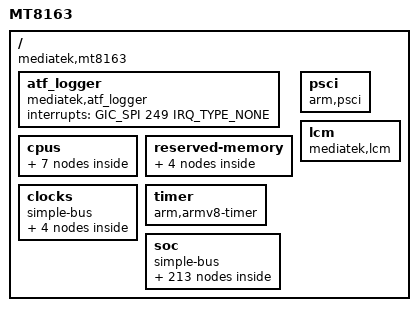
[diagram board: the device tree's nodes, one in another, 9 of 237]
/*
 * Mediatek's MT8163 SoC device tree source
 * Copyright (c) 2014-2015 MediaTek Inc.
 *
 * This program is free software; you can redistribute it and/or modify
 * it under the terms of the GNU General Public License version 2 as
 * published by the Free Software Foundation.
 *
 * This program is distributed in the hope that it will be useful,
 * MERCHANTABILITY or FITNESS FOR A PARTICULAR PURPOSE.  See the
 * GNU General Public License for more details.
 */

#include <dt-bindings/clock/mt8163-clk.h>
#include <dt-bindings/power/mt8163-power.h>
#include <dt-bindings/interrupt-controller/irq.h>
#include <dt-bindings/interrupt-controller/arm-gic.h>
#include <dt-bindings/reset-controller/mt8163-resets.h>
#include <dt-bindings/soc/mt8163-md32.h>
#include "mt8163-pinfunc.h"

/ {
	model = "MT8163";
	compatible = "mediatek,mt8163";
	interrupt-parent = <&sysirq>;
	#address-cells = <2>;
	#size-cells = <2>;

	/* ATF logger SW IRQ number 281 = 32 + 249 */
	atf_logger {
		compatible = "mediatek,atf_logger";
		interrupts = <GIC_SPI 249 IRQ_TYPE_NONE>;
	};

	cpus {
		#address-cells = <1>;
		#size-cells = <0>;

		cpu0: cpu@0 {
			device_type = "cpu";
			compatible = "arm,cortex-a53";
			reg = <0x0>;
			enable-method = "mt-boot";
			cpu-idle-states = <&CLUSTER_SLEEP_0 &CLUSTER_SLEEP_0>,
					  <&CPU_SLEEP_0_0 &CPU_SLEEP_0_0 &CPU_SLEEP_0_0>;
			cpu-release-addr = <0x0 0x40000200>;
			clock-frequency = <1300000000>;
		};

		cpu1: cpu@1 {
			device_type = "cpu";
			compatible = "arm,cortex-a53";
			reg = <0x1>;
			enable-method = "mt-boot";
			cpu-idle-states = <&CLUSTER_SLEEP_0 &CLUSTER_SLEEP_0>,
					  <&CPU_SLEEP_0_0 &CPU_SLEEP_0_0 &CPU_SLEEP_0_0>;
			cpu-release-addr = <0x0 0x40000200>;
			clock-frequency = <1300000000>;
		};

		cpu2: cpu@2 {
			device_type = "cpu";
			compatible = "arm,cortex-a53";
			reg = <0x2>;
			enable-method = "mt-boot";
			cpu-idle-states = <&CLUSTER_SLEEP_0 &CLUSTER_SLEEP_0>,
					  <&CPU_SLEEP_0_0 &CPU_SLEEP_0_0 &CPU_SLEEP_0_0>;
			cpu-release-addr = <0x0 0x40000200>;
			clock-frequency = <1300000000>;
		};

		cpu3: cpu@3 {
			device_type = "cpu";
			compatible = "arm,cortex-a53";
			reg = <0x3>;
			enable-method = "mt-boot";
			cpu-idle-states = <&CLUSTER_SLEEP_0 &CLUSTER_SLEEP_0>,
					  <&CPU_SLEEP_0_0 &CPU_SLEEP_0_0 &CPU_SLEEP_0_0>;
			cpu-release-addr = <0x0 0x40000200>;
			clock-frequency = <1300000000>;
		};

		idle-states {
			entry-method = "arm,psci";

			CPU_SLEEP_0_0: cpu-sleep-0-0 {
				compatible = "arm,idle-state";
				arm,psci-suspend-param = <0x0010000>;
				entry-latency-us = <600>;
				exit-latency-us = <600>;
				min-residency-us = <1200>;
			};

			CLUSTER_SLEEP_0: cluster-sleep-0 {
				compatible = "arm,idle-state";
				arm,psci-suspend-param = <0x2010000>;
				entry-latency-us = <800>;
				exit-latency-us = <1000>;
				min-residency-us = <2000>;
			};
		};
	};

	reserved-memory {
		#address-cells = <2>;
		#size-cells = <2>;
		ranges;

		atf-reserved-memory@43000000 {
			compatible = "mediatek,mt8163-atf-reserved-memory";
			no-map;
			reg = <0 0x43000000 0 0x30000>;
		};

		ram_console-reserved-memory@44400000{
			compatible = "mediatek,ram_console";
			reg = <0 0x44400000 0 0x10000>;
		};

		minirdump-reserved-memory@444f0000{
			compatible = "mediatek,minirdump";
			reg = <0 0x444f0000 0 0x10000>;
		};

		consys-reserve-memory {
			compatible = "mediatek,consys-reserve-memory";
			no-map;
			size = <0 0x200000>;
			alignment = <0 0x200000>;
		};
	};

	psci {
		compatible  = "arm,psci";
		method      = "smc";
		cpu_suspend = <0x84000001>;
		cpu_off     = <0x84000002>;
		cpu_on      = <0x84000003>;
		affinity_info = <0x84000004>;
	};

	clocks {
		#address-cells = <2>;
		#size-cells = <2>;
		compatible = "simple-bus";
		ranges;

		clk_null: clk_null {
			compatible = "fixed-clock";
			#clock-cells = <0>;
			clock-frequency = <0>;
		};

		clk26m: clk26m {
			compatible = "fixed-clock";
			#clock-cells = <0>;
			clock-frequency = <26000000>;
		};

		clk32k: clk32k {
			compatible = "fixed-clock";
			#clock-cells = <0>;
			clock-frequency = <32000>;
		};

		uart_clk: dummy26m {
			compatible = "fixed-clock";
			clock-frequency = <26000000>;
			#clock-cells = <0>;
		};
	};

	timer {
		compatible = "arm,armv8-timer";
		interrupt-parent = <&gic>;
		interrupts = <GIC_PPI 13
			     (GIC_CPU_MASK_SIMPLE(4) | IRQ_TYPE_LEVEL_LOW)>,
			     <GIC_PPI 14
			     (GIC_CPU_MASK_SIMPLE(4) | IRQ_TYPE_LEVEL_LOW)>,
			     <GIC_PPI 11
			     (GIC_CPU_MASK_SIMPLE(4) | IRQ_TYPE_LEVEL_LOW)>,
			     <GIC_PPI 10
			     (GIC_CPU_MASK_SIMPLE(4) | IRQ_TYPE_LEVEL_LOW)>;
		clock-frequency = <13000000>;
	};

	soc {
		#address-cells = <2>;
		#size-cells = <2>;
		compatible = "simple-bus";
		ranges;

		chipid: chipid@08000000 {
			compatible = "mediatek,mt8163-chipid";
			reg = <0 0x08000000 0 0x0010>;
		};

		topckgen: topckgen@10000000 {
			compatible = "mediatek,mt8163-topckgen";
			reg = <0 0x10000000 0 0x1000>;
			#clock-cells = <1>;
		};

		infracfg: infracfg@10001000 {
			compatible = "mediatek,mt8163-infracfg", "syscon";
			reg = <0 0x10001000 0 0x1000>;
			#clock-cells = <1>;
			#reset-cells = <1>;
		};

		syscfg_pctl_a: syscfg_pctl_a@10005000 {
			compatible = "mediatek,mt8163-pctl-a-syscfg", "syscon";
			reg = <0 0x10005000 0 0x1000>;
		};

		toprgu: toprgu@10007000 {
			compatible = "mediatek,mt8163-rgu";
			reg = <0 0x10007000 0 0x1000>;
			interrupts = <GIC_SPI 128 IRQ_TYPE_EDGE_FALLING>;
			#reset-cells = <1>;
		};

		apxgpt: apxgpt@10008000 {
			compatible = "mediatek,mt8163-apxgpt";
			reg = <0 0x10008000 0 0x1000>;
			interrupts = <GIC_SPI 152 IRQ_TYPE_LEVEL_LOW>;
			clocks = <&infracfg CLK_INFRA_APXGPT>,
				 <&infracfg CLK_INFRA_CLK_13M>,
				 <&topckgen CLK_TOP_RTC_SEL>;
			clock-names = "bus",
				      "clk13m",
				      "rtc_sel";
		};

		pmu {
			compatible = "arm,armv8-pmuv3";
			interrupts = <GIC_SPI 8 IRQ_TYPE_LEVEL_LOW>,
				<GIC_SPI 9 IRQ_TYPE_LEVEL_LOW>,
				<GIC_SPI 10 IRQ_TYPE_LEVEL_LOW>,
				<GIC_SPI 11 IRQ_TYPE_LEVEL_LOW>;
			interrupt-affinity = <&cpu0>,
					     <&cpu1>,
					     <&cpu2>,
					     <&cpu3>;
		};

		pio: pinctrl@10005000 {
			compatible = "mediatek,mt8163-pinctrl";
			reg = <0 0x1000B000 0 0x1000>;
			mediatek,pctl-regmap = <&syscfg_pctl_a>;
			pins-are-numbered;
			gpio-controller;
			#gpio-cells = <2>;
			interrupt-controller;
			#interrupt-cells = <2>;
			interrupts = <GIC_SPI 153 IRQ_TYPE_LEVEL_HIGH>,
				     <GIC_SPI 154 IRQ_TYPE_LEVEL_HIGH>,
				     <GIC_SPI 155 IRQ_TYPE_LEVEL_HIGH>;

			spi_pins_a: spi1 {
				pins_spi {
					pinmux = <MT8163_PIN_53_SPI_CS__FUNC_SPI_CSB>,
						 <MT8163_PIN_54_SPI_CK__FUNC_SPI_CLK>,
						 <MT8163_PIN_55_SPI_MI__FUNC_SPI_MI>,
						 <MT8163_PIN_56_SPI_MO__FUNC_SPI_MO>;
					bias-disable;
				};
			};

			/* UART GPIO Settings - Start */
			/* UART0: rx set, rx clear, tx clear, tx clear*/
			uart0_gpio_def_cfg:uart0gpiodefault {

			};
			uart0_rx_set_cfg:uart0_rx_set {
				pins_cmd_dat {
					pinmux = <MT8163_PIN_79_URXD0__FUNC_URXD0>;
				};
			};
			uart0_rx_clr_cfg:uart0_rx_clear  {
				pins_cmd_dat {
					pinmux = <MT8163_PIN_79_URXD0__FUNC_GPIO79>;
					slew-rate = <1>;
					output-high;
				};
			};
			uart0_tx_set_cfg:uart0_tx_set  {
				pins_cmd_dat {
					pinmux = <MT8163_PIN_80_UTXD0__FUNC_UTXD0>;
				};
			};
			uart0_tx_clr_cfg:uart0_tx_clear  {
				pins_cmd_dat {
					pinmux = <MT8163_PIN_80_UTXD0__FUNC_GPIO80>;
					slew-rate = <1>;
					output-high;
				};
			};

			/* UART1: rx set, rx clear, tx clear, tx clear*/
			uart1_gpio_def_cfg:uart1gpiodefault {

			};
			uart1_rx_set_cfg:uart1_rx_set {
				pins_cmd_dat {
					pinmux = <MT8163_PIN_81_URXD1__FUNC_URXD1>;
				};
			};
			uart1_rx_clr_cfg:uart1_rx_clear {
				pins_cmd_dat {
					pinmux = <MT8163_PIN_81_URXD1__FUNC_GPIO81>;
					slew-rate = <1>;
					output-high;
				};
			};
			uart1_tx_set_cfg:uart1_tx_set {
				pins_cmd_dat {
					pinmux = <MT8163_PIN_82_UTXD1__FUNC_UTXD1>;
				};
			};
			uart1_tx_clr_cfg:uart1_tx_clear {
				pins_cmd_dat {
					pinmux = <MT8163_PIN_82_UTXD1__FUNC_GPIO82>;
					slew-rate = <1>;
					output-high;
				};
			};

			/* UART2: rx set, rx clear, tx clear, tx clear*/
			uart2_gpio_def_cfg:uart2gpiodefault {

			};
			uart2_rx_set_cfg:uart2_rx_set {
				pins_cmd_dat {
					pinmux = <MT8163_PIN_14_URXD2__FUNC_URXD2>;
				};
			};
			uart2_rx_clr_cfg:uart2_rx_clear {
				pins_cmd_dat {
					pinmux = <MT8163_PIN_14_URXD2__FUNC_GPIO14>;
					slew-rate = <1>;
					output-high;
				};
			};
			uart2_tx_set_cfg:uart2_tx_set {
				pins_cmd_dat {
					pins = <MT8163_PIN_15_UTXD2__FUNC_UTXD2>;
				};
			};
			uart2_tx_clr_cfg:uart2_tx_clear {
				pins_cmd_dat {
					pinmux = <MT8163_PIN_15_UTXD2__FUNC_GPIO15>;
					slew-rate = <1>;
					output-high;
				};
			};

			/* UART3: rx set, rx clear, tx clear, tx clear*/
			uart3_gpio_def_cfg:uart3gpiodefault {

			};
			uart3_rx_set_cfg:uart3_rx_set {
				pins_cmd_dat {
					pinmux = <MT8163_PIN_16_URXD3__FUNC_URXD3>;
				};
			};
			uart3_rx_clr_cfg:uart3_rx_clear {
				pins_cmd_dat {
					pinmux = <MT8163_PIN_16_URXD3__FUNC_GPIO16>;
					slew-rate = <1>;
					output-high;
				};
			};
			uart3_tx_set_cfg:uart3_tx_set {
				pins_cmd_dat {
					pinmux = <MT8163_PIN_17_UTXD3__FUNC_UTXD3>;
				};
			};
			uart3_tx_clr_cfg:uart3_tx_clear {
				pins_cmd_dat {
					pinmux = <MT8163_PIN_17_UTXD3__FUNC_GPIO17>;
					slew-rate = <1>;
					output-high;
				};
			};

			/* UART GPIO Settings - End */
		};

		dramco: dramco@10004000 {
			compatible = "mediatek,mt8163-dramco";
			reg = <0 0x10004000 0 0x1000>;
		};

		scpsys: scpsys@10006000 {
			compatible = "mediatek,mt8163-scpsys", "syscon";
			#power-domain-cells = <1>;
			reg = <0 0x10006000 0 0x1000>;
			interrupts =	<GIC_SPI 163 IRQ_TYPE_LEVEL_LOW>,
					<GIC_SPI 164 IRQ_TYPE_LEVEL_LOW>,
					<GIC_SPI 165 IRQ_TYPE_LEVEL_LOW>,
					<GIC_SPI 166 IRQ_TYPE_LEVEL_LOW>,
					<GIC_SPI 167 IRQ_TYPE_LEVEL_LOW>,
					<GIC_SPI 168 IRQ_TYPE_LEVEL_LOW>,
					<GIC_SPI 169 IRQ_TYPE_LEVEL_LOW>,
					<GIC_SPI 170 IRQ_TYPE_LEVEL_LOW>;
			infracfg = <&infracfg>;
			clocks = <&topckgen CLK_TOP_MFG_SEL>,
				 <&topckgen CLK_TOP_MM_SEL>;
			clock-names = "mfg", "mm";
		};

		hacc@1000a000 {
			compatible = "mediatek,hacc";
			reg = <0 0x1000a000 0 0x1000>;
			clocks = <&infracfg CLK_INFRA_SEJ>;
			clock-names = "main";
		};

		apmixedsys: apmixedsys@1000c000 {
			compatible = "mediatek,mt8163-apmixedsys";
			reg = <0 0x1000c000 0 0x1000>;
			#clock-cells = <1>;
		};

		fhctl@1000cf00 {
			compatible = "mediatek,mt8163-fhctl";
			reg = <0 0x1000cf00 0 0x100>;
		};

		pwrap: pwrap@0x1000d000 {
			compatible = "mediatek,mt8163-pwrap";
			reg = <0 0x1000d000 0 0x1000>;
			reg-names = "pwrap-base";
			interrupts = <GIC_SPI 161 IRQ_TYPE_LEVEL_HIGH>;
			clocks = <&topckgen CLK_TOP_PMICSPI_SEL>,
				 <&infracfg CLK_INFRA_PMIC_AP>;
			clock-names = "spi",
				      "pwrap";
		};

		devapc_ao@1000e000 {
			compatible = "mediatek,mt8163-devapc_ao";
			reg = <0 0x1000e000 0 0x1000>;
		};

		ddrphy: ddrphy@1000f000 {
			compatible = "mediatek,mt8163-ddrphy", "mediatek,ddrphy";
			reg = <0 0x1000f000 0 0x1000>;
			clocks = <&infracfg CLK_INFRA_DRAMC_F26M>;
			clock-names = "dramc_f26m";
		};

		keypad: keypad@10010000 {
			compatible = "mediatek,mt8163-keypad";
			reg = <0 0x10010000 0 0x1000>;
			interrupts = <GIC_SPI 162 IRQ_TYPE_EDGE_FALLING>;
		};

		md32: md32@10020000 {
			compatible = "mediatek,mt8163-md32";
			reg = <0 0x10020000 0 0x38000>,
			      <0 0x10058000 0 0x400>,
			      <0 0x10059000 0 0x400>;
			interrupts = <GIC_SPI 174 IRQ_TYPE_LEVEL_HIGH>;
			clocks = <&infracfg CLK_INFRA_SCPSYS>;
			clock-names = "sys";
			status = "disabled";
		};

		mcucfg: mcucfg@10200000 {
			compatible = "mediatek,mt8173-mcucfg", "syscon";
			reg = <0 0x10200000 0 0x1000>;
		};

		cpuxgpt: cpuxgpt@10200000 {
			compatible = "mediatek,mt8163-cpuxgpt";
			interrupts = <GIC_SPI 64 IRQ_TYPE_LEVEL_HIGH>,
				<GIC_SPI 65 IRQ_TYPE_LEVEL_HIGH>,
				<GIC_SPI 66 IRQ_TYPE_LEVEL_HIGH>,
				<GIC_SPI 67 IRQ_TYPE_LEVEL_HIGH>;
		};

		lastpc: lastpc@10200000 {
			compatible = "mediatek,mt8163-mcucfg";
			reg = <0 0x10200000 0 0x200>;
		};

		sysirq: intpol-controller@10200620 {
			compatible = "mediatek,mt8163-sysirq",
				     "mediatek,mt6577-sysirq";
			interrupt-controller;
			#interrupt-cells = <3>;
			interrupt-parent = <&gic>;
			reg = <0 0x10200620 0 0x20>;
		};

		emi: emi@10203000 {
			compatible = "mediatek,mt8163-emi", "mediatek,emi";
			reg = <0 0x10203000 0 0x1000>;
			interrupts = <GIC_SPI 133 IRQ_TYPE_LEVEL_HIGH>;
		};

		sys_cirq: sys_cirq@10204000 {
			compatible = "mediatek,mt8163-sys_cirq",
				     "mediatek,mt6735-sys_cirq";
			reg = <0 0x10204000 0 0x1000>;
			interrupts = <GIC_SPI 240 IRQ_TYPE_LEVEL_LOW>;
			mediatek,cirq_num = <169>;
			mediatek,spi_start_offset = <72>;
		};

		m4u@10205000 {
			cell-index = <0>;
			compatible = "mediatek,mt8163-m4u";
			reg = <0 0x10205000 0 0x1000>;
			interrupts = <GIC_SPI 147 IRQ_TYPE_LEVEL_LOW>;
		};

		devapc@10207000 {
			compatible = "mediatek,mt8163-devapc";
			reg = <0 0x10207000 0 0x1000>;
			interrupts = <GIC_SPI 133 IRQ_TYPE_LEVEL_LOW>;
			clocks = <&infracfg CLK_INFRA_DEVICE_APC>;
			clock-names = "main";
		};

		systracker: systracker@10208000 {
			compatible = "mediatek,bus_dbg-v1";
			reg = <0 0x10208000 0 0x1000>;
			interrupts = <GIC_SPI 132 IRQ_TYPE_LEVEL_LOW>;
		};

		dramc_nao: dramc_nao@1020e000 {
			compatible = "mediatek,mt8163-dramc_nao", "mediatek,dramc_nao";
			reg = <0 0x1020e000 0 0x1000>;
		};

		gcpu: gcpu@10210000 {
			compatible = "mediatek,mt8163-gcpu";
			reg = <0 0x10210000 0 0x1000>;
			clocks = <&infracfg CLK_INFRA_GCPU>;
			clock-names = "main";
		};

		gce: gce@10212000 {
			compatible = "mediatek,mt8163-gce";
			reg = <0 0x10212000 0 0x1000>;
			interrupts = <GIC_SPI 143 IRQ_TYPE_LEVEL_LOW>,
				     <GIC_SPI 144 IRQ_TYPE_LEVEL_LOW>;
			disp_mutex_reg = <0x14015000 0x1000>;
			g3d_config_base = <0x13000000 0 0xffff0000>;
			mmsys_config_base = <0x14000000 1 0xffff0000>;
			disp_dither_base = <0x14010000 2 0xffff0000>;
			mm_na_base = <0x14020000 3 0xffff0000>;
			imgsys_base = <0x15000000 4 0xffff0000>;
			vdec_gcon_base = <0x16000000 5 0xffff0000>;
			venc_gcon_base = <0x17000000 6 0xffff0000>;
			conn_peri_base = <0x18000000 7 0xffff0000>;
			topckgen_base = <0x10000000 8 0xffff0000>;
			kp_base = <0x10010000 9 0xffff0000>;
			scp_sram_base = <0x10020000 10 0xffff0000>;
			infra_na3_base = <0x10030000 11 0xffff0000>;
			infra_na4_base = <0x10040000 12 0xffff0000>;
			scp_base = <0x10050000 13 0xffff0000>;
			mcucfg_base = <0x10200000 14 0xffff0000>;
			gcpu_base = <0x10210000 15 0xffff0000>;
			usb0_base = <0x11200000 16 0xffff0000>;
			usb_sif_base = <0x11210000 17 0xffff0000>;
			audio_base = <0x11220000 18 0xffff0000>;
			msdc0_base = <0x11230000 19 0xffff0000>;
			msdc1_base = <0x11240000 20 0xffff0000>;
			msdc2_base = <0x11250000 21 0xffff0000>;
			msdc3_base = <0x11260000 22 0xffff0000>;

			mdp_rdma0_sof = <0>;
			mdp_rsz0_sof = <1>;
			mdp_rsz1_sof = <2>;
			mdp_tdshp_sof = <3>;
			mdp_wdma_sof = <4>;
			mdp_wrot_sof = <5>;
			disp_ovl0_sof = <6>;
			disp_ovl1_sof = <7>;
			disp_rdma0_sof = <8>;
			disp_rdma1_sof = <9>;
			disp_wdma0_sof = <10>;
			disp_color_sof = <11>;
			disp_ccorr_sof = <12>;
			disp_aal_sof = <13>;
			disp_gamma_sof = <14>;
			disp_dither_sof = <15>;
			disp_ufoe_sof = <16>;
			disp_pwm0_sof = <17>;
			disp_wdma1_sof = <18>;
			ufod_rdma0_l0_sof = <19>;
			ufod_rdma0_l1_sof = <20>;
			ufod_rdma0_l2_sof = <21>;
			ufod_rdma0_l3_sof = <22>;
			ufod_rdma1_l0_sof = <23>;
			ufod_rdma1_l1_sof = <24>;
			ufod_rdma1_l2_sof = <25>;
			ufod_rdma1_l3_sof = <26>;
			disp_dsc_sof = <27>;
			mdp_rdma0_frame_done = <28>;
			mdp_rsz0_frame_done = <29>;
			mdp_rsz1_frame_done = <30>;
			mdp_tdshp_frame_done = <31>;
			mdp_wdma_frame_done = <32>;
			mdp_wrot_write_frame_done = <33>;
			mdp_wrot_read_frame_done = <34>;
			disp_ovl0_frame_done = <35>;
			disp_ovl1_frame_done = <36>;
			disp_rdma0_frame_done = <37>;
			disp_rdma1_frame_done = <38>;
			disp_wdma0_frame_done = <39>;
			disp_color_frame_done = <40>;
			disp_ccorr_frame_done = <41>;
			disp_aal_frame_done = <42>;
			disp_gamma_frame_done = <43>;
			disp_dither_frame_done = <44>;
			disp_ufoe_frame_done = <45>;
			disp_dpi0_frame_done = <46>;
			disp_wdma1_frame_done = <47>;
			ufod_rdma0_l0_frame_done = <48>;
			ufod_rdma0_l1_frame_done = <49>;
			ufod_rdma0_l2_frame_done = <50>;
			ufod_rdma0_l3_frame_done = <51>;
			ufod_rdma1_l0_frame_done = <52>;
			ufod_rdma1_l1_frame_done = <53>;
			ufod_rdma1_l2_frame_done = <54>;
			ufod_rdma1_l3_frame_done = <55>;
			disp_dpi1_frame_done = <56>;
			disp_dsc_frame_done = <57>;
			stream_done_0 = <58>;
			stream_done_1 = <59>;
			stream_done_2 = <60>;
			stream_done_3 = <61>;
			stream_done_4 = <62>;
			stream_done_5 = <63>;
			stream_done_6 = <64>;
			stream_done_7 = <65>;
			stream_done_8 = <66>;
			stream_done_9 = <67>;
			buf_underrun_event_0 = <68>;
			buf_underrun_event_1 = <69>;
			dsi0_te_event = <70>;
			isp_frame_done_b = <130>;
			isp_frame_done_a = <131>;
			isp_frame_done_p2_0 = <131>;
			isp_frame_done_p2_1 = <130>;
			seninf_1_fifo_full = <135>;
			venc_done = <257>;
			jpgenc_done = <258>;
			jpgdec_done = <259>;
			venc_mb_done = <260>;
			venc_128byte_cnt_done = <261>;

			clocks = <&infracfg CLK_INFRA_GCE>,
				 <&mmsys CLK_MM_SMI_COMMON>,
				 <&mmsys CLK_MM_SMI_LARB0>,
				 <&mmsys CLK_MM_CAM_MDP>,
				 <&mmsys CLK_MM_MDP_RDMA>,
				 <&mmsys CLK_MM_MDP_RSZ0>,
				 <&mmsys CLK_MM_MDP_RSZ1>,
				 <&mmsys CLK_MM_MDP_TDSHP>,
				 <&mmsys CLK_MM_MDP_WROT>,
				 <&mmsys CLK_MM_MDP_WDMA>;

			clock-names = "MT_CG_INFRA_GCE",
				      "MT_CG_DISP0_SMI_COMMON",
				      "MT_CG_DISP0_SMI_LARB0",
				      "MT_CG_DISP0_CAM_MDP",
				      "MT_CG_DISP0_MDP_RDMA",
				      "MT_CG_DISP0_MDP_RSZ0",
				      "MT_CG_DISP0_MDP_RSZ1",
				      "MT_CG_DISP0_MDP_TDSHP",
				      "MT_CG_DISP0_MDP_WROT",
				      "MT_CG_DISP0_MDP_WDMA";
		};

		perisys_iommu@10214000 {
			cell-index = <1>;
			compatible = "mediatek,mt8163-perisys_iommu";
			reg = <0 0x10214000 0 0x1000>;
			interrupts = <GIC_SPI 145 IRQ_TYPE_LEVEL_LOW>;
		};

		gic: interrupt-controller@10221000 {
			compatible = "arm,gic-400";
			interrupt-controller;
			#interrupt-cells = <3>;
			interrupt-parent = <&gic>;
			reg = <0 0x10221000 0 0x1000>,
			      <0 0x10222000 0 0x1000>,
			      <0 0x10224000 0 0x2000>,
			      <0 0x10226000 0 0x2000>;
			interrupts = <GIC_PPI 9
				     (GIC_CPU_MASK_SIMPLE(4) | IRQ_TYPE_LEVEL_HIGH)>;
		};

		btif_tx: btif_tx@11000700 {
			compatible = "mediatek,btif_tx";
			reg = <0 0x11000700 0 0x80>;
			interrupts = <GIC_SPI 110 IRQ_TYPE_LEVEL_LOW>;
		};

		btif_rx: btif_rx@11000780 {
			compatible = "mediatek,btif_rx";
			reg = <0 0x11000780 0 0x80>;
			interrupts = <GIC_SPI 111 IRQ_TYPE_LEVEL_LOW>;
		};

		auxadc: auxadc@11001000 {
			compatible = "mediatek,mt8163-auxadc",
				     "mediatek,mt6735-auxadc";
			reg = <0 0x11001000 0 0x1000>;
			interrupts = <GIC_SPI 76 IRQ_TYPE_EDGE_FALLING>;
			clocks = <&infracfg CLK_INFRA_AUXADC>;
			clock-names = "auxadc-main";
		};

		uart0: uart0@11002000 {
			cell-index = <0>;
			compatible = "mediatek,mt8163-uart";
			reg = <0 0x11002000 0 0x1000>, /* UART base */
			      <0 0x11000300 0 0x1000>, /* DMA Tx base */
			      <0 0x11000380 0 0x80>; /* DMA Rx base */
			interrupts = <GIC_SPI 91 IRQ_TYPE_LEVEL_LOW>, /* UART IRQ */
				     <GIC_SPI 102 IRQ_TYPE_LEVEL_LOW>, /* DMA Tx IRQ */
				     <GIC_SPI 103 IRQ_TYPE_LEVEL_LOW>; /* DMA Rx IRQ */

			clock-frequency = <26000000>;
			clock-div = <1>;
			clocks = <&infracfg CLK_INFRA_UART0>, <&infracfg CLK_INFRA_AP_DMA>;
			clock-names = "uart0-main", "uart-apdma";
			pinctrl-names = "uart0_gpio_default",
					"uart0_rx_set",
					"uart0_rx_clear",
					"uart0_tx_set",
					"uart0_tx_clear";

			pinctrl-0 = <&uart0_gpio_def_cfg>;
			pinctrl-1 = <&uart0_rx_set_cfg>;
			pinctrl-2 = <&uart0_rx_clr_cfg>;
			pinctrl-3 = <&uart0_tx_set_cfg>;
			pinctrl-4 = <&uart0_tx_clr_cfg>;
			rx_gpios = <&pio 79 0>;
			tx_gpios = <&pio 80 0>;
			status = "okay";
		};

		uart1: uart1@11003000 {
			cell-index = <1>;
			compatible = "mediatek,mt8163-uart";
			reg = <0 0x11003000 0 0x1000>, /* UART base */
			      <0 0x11000400 0 0x80>, /* DMA Tx base */
			      <0 0x11000480 0 0x80>; /* DMA Rx base */
			interrupts = <GIC_SPI 92 IRQ_TYPE_LEVEL_LOW>, /* UART IRQ */
				     <GIC_SPI 104 IRQ_TYPE_LEVEL_LOW>, /* DMA Tx IRQ */
				     <GIC_SPI 105 IRQ_TYPE_LEVEL_LOW>; /* DMA Rx IRQ */

			clock-frequency = <26000000>;
			clock-div = <1>;
			clocks = <&infracfg CLK_INFRA_UART1>;
			clock-names = "uart1-main";

			pinctrl-names = "uart1_gpio_default",
					"uart1_rx_set",
					"uart1_rx_clear",
					"uart1_tx_set",
					"uart1_tx_clear";

			pinctrl-0 = <&uart1_gpio_def_cfg>;
			pinctrl-1 = <&uart1_rx_set_cfg>;
			pinctrl-2 = <&uart1_rx_clr_cfg>;
			pinctrl-3 = <&uart1_tx_set_cfg>;
			pinctrl-4 = <&uart1_tx_clr_cfg>;
			rx_gpios = <&pio 81 0>;
			tx_gpios = <&pio 82 0>;
			status = "disable";
		};

		uart2: uart2@11004000 {
			cell-index = <2>;
			compatible = "mediatek,mt8163-uart";
			reg = <0 0x11004000 0 0x1000>, /* UART base */
			      <0 0x11000500 0 0x80>, /* DMA Tx base */
			      <0 0x11000580 0 0x80>; /* DMA Rx base */
			interrupts = <GIC_SPI 93 IRQ_TYPE_LEVEL_LOW>, /* UART IRQ */
				     <GIC_SPI 106 IRQ_TYPE_LEVEL_LOW>, /* DMA Tx IRQ */
				     <GIC_SPI 107 IRQ_TYPE_LEVEL_LOW>; /* DMA Rx IRQ */

			clock-frequency = <26000000>;
			clock-div = <1>;
			clocks = <&infracfg CLK_INFRA_UART2>;
			clock-names = "uart2-main";
			pinctrl-names = "uart2_gpio_default",
					"uart2_rx_set",
					"uart2_rx_clear",
					"uart2_tx_set",
					"uart2_tx_clear";

			pinctrl-0 = <&uart2_gpio_def_cfg>;
			pinctrl-1 = <&uart2_rx_set_cfg>;
			pinctrl-2 = <&uart2_rx_clr_cfg>;
			pinctrl-3 = <&uart2_tx_set_cfg>;
			pinctrl-4 = <&uart2_tx_clr_cfg>;
			rx_gpios = <&pio 14 0>;
			tx_gpios = <&pio 15 0>;
			status = "disable";
		};

		uart3: uart3@11005000 {
			cell-index = <3>;
			compatible = "mediatek,mt8163-uart";
			reg = <0 0x11005000 0 0x1000>, /* UART base */
			      <0 0x11000600 0 0x80>, /* DMA Tx base */
			      <0 0x11000680 0 0x80>; /* DMA Rx base */
			interrupts = <GIC_SPI 94 IRQ_TYPE_LEVEL_LOW>, /* UART IRQ */
				     <GIC_SPI 108 IRQ_TYPE_LEVEL_LOW>, /* DMA Tx IRQ */
				     <GIC_SPI 109 IRQ_TYPE_LEVEL_LOW>; /* DMA Rx IRQ */

			clock-frequency = <26000000>;
			clock-div = <1>;
			clocks = <&infracfg CLK_INFRA_UART3>;
			clock-names = "uart3-main";

			pinctrl-names = "uart3_gpio_default",
					"uart3_rx_set",
					"uart3_rx_clear",
					"uart3_tx_set",
					"uart3_tx_clear";

			pinctrl-0 = <&uart3_gpio_def_cfg>;
			pinctrl-1 = <&uart3_rx_set_cfg>;
			pinctrl-2 = <&uart3_rx_clr_cfg>;
			pinctrl-3 = <&uart3_tx_set_cfg>;
			pinctrl-4 = <&uart3_tx_clr_cfg>;
			rx_gpios = <&pio 16 0>;
			tx_gpios = <&pio 17 0>;
			status = "disable";
		};

		pwm: pwm@11006000 {
			compatible = "mediatek,mt8163-pwm";
			reg = <0 0x11006000 0 0x1000>;
			interrupts = <GIC_SPI 77 IRQ_TYPE_LEVEL_LOW>;
			clocks = <&infracfg CLK_INFRA_PWM>,
				 <&infracfg CLK_INFRA_PWM1>,
				 <&infracfg CLK_INFRA_PWM2>,
				 <&infracfg CLK_INFRA_PWM3>;

			clock-names = "PWM-main",
				      "PWM1-main",
				      "PWM2-main",
				      "PWM3-main";
		};

		i2c0: i2c@11007000 {
			compatible = "mediatek,mt8173-i2c";
			reg = <0 0x11007000 0 0x70>,
			      <0 0x11000180 0 0x80>;
			interrupts = <GIC_SPI 84 IRQ_TYPE_LEVEL_LOW>;
			clock-div = <10>;
			clocks = <&infracfg CLK_INFRA_I2C0>, <&infracfg CLK_INFRA_AP_DMA>;
			clock-names = "main", "dma";
			#address-cells = <1>;
			#size-cells = <0>;
			status = "disabled";
		};

		i2c1: i2c@11008000 {
			compatible = "mediatek,mt8173-i2c";
			reg = <0 0x11008000 0 0x70>,
			      <0 0x11000200 0 0x80>;
			interrupts = <GIC_SPI 85 IRQ_TYPE_LEVEL_LOW>;
			clock-div = <10>;
			clocks = <&infracfg CLK_INFRA_I2C1>, <&infracfg CLK_INFRA_AP_DMA>;
			clock-names = "main", "dma";
			#address-cells = <1>;
			#size-cells = <0>;
			status = "disabled";
		};

		i2c2: i2c@11009000 {
			compatible = "mediatek,mt8173-i2c";
			reg = <0 0x11009000 0 0x70>,
			      <0 0x11000280 0 0x80>;
			interrupts = <GIC_SPI 86 IRQ_TYPE_LEVEL_LOW>;
			clock-div = <10>;
			clocks = <&infracfg CLK_INFRA_I2C2>, <&infracfg CLK_INFRA_AP_DMA>;
			clock-names = "main", "dma";
			#address-cells = <1>;
			#size-cells = <0>;
			status = "disabled";
		};

		spi: spi@1100a000 {
			compatible = "mediatek,mt8163-spi";
			#address-cells = <1>;
			#size-cells = <0>;
			reg = <0 0x1100a000 0 0x1000>;
			interrupts = <GIC_SPI 118 IRQ_TYPE_LEVEL_LOW>;
			clocks = <&topckgen CLK_TOP_SYSPLL3_D2>,
				 <&topckgen CLK_TOP_SPI_SEL>,
				 <&infracfg CLK_INFRA_SPI>;
			clock-names = "parent-clk", "sel-clk", "spi-clk";
			pinctrl-names = "default";
			pinctrl-0 = <&spi_pins_a>;
			status = "disabled";
		};

		thermal: thermal@1100b000 {
			compatible = "mediatek,mt8163-thermal";
			reg = <0 0x1100b000 0 0x1000>;
			interrupts = <GIC_SPI 78 IRQ_TYPE_LEVEL_LOW>;
			clocks = <&infracfg CLK_INFRA_THERM>, <&infracfg CLK_INFRA_AUXADC>;
			clock-names = "therm", "auxadc";
			apmixedsys = <&apmixedsys>;
		};

		ptp_od: ptp_od@1100b000 {
			compatible = "mediatek,mt8163-ptp_od";
			reg = <0 0x1100b000 0 0x1000>;
			interrupts = <GIC_SPI 125 IRQ_TYPE_LEVEL_LOW>;
			clocks = <&infracfg CLK_INFRA_THERM>;
			clock-names = "ptp_infra_therm";
		};

		btif: btif@1100c000 {
			compatible = "mediatek,btif";
			reg = <0 0x1100c000 0 0x1000>;
			interrupts = <GIC_SPI 112 IRQ_TYPE_LEVEL_LOW>;
			clocks = <&infracfg CLK_INFRA_BTIF>, <&infracfg CLK_INFRA_AP_DMA>;
			clock-names = "btifc", "apdmac";
		};/* End of btif */

		nfi: nfi@1100d000 {
			compatible = "mediatek,mt8163-nfi";
			reg = <0 0x1100d000 0 0x1000>;
			interrupts = <GIC_SPI 96 IRQ_TYPE_LEVEL_LOW>;
			clocks = <&infracfg CLK_INFRA_NFI>, <&infracfg CLK_INFRA_NFI_ECC>,
				 <&infracfg CLK_INFRA_NFI_BCLK>, <&topckgen CLK_TOP_ONFI_SEL>,
				 <&clk26m>, <&topckgen CLK_TOP_SYSPLL2_D2>,
				 <&topckgen CLK_TOP_SYSPLL_D7>, <&infracfg CLK_INFRA_NFI_SEL>,
				 <&topckgen CLK_TOP_AXI_SEL>, <&infracfg CLK_INFRA_ONFI_D2>,
				 <&infracfg CLK_INFRA_NFI_ECC_66M>, <&infracfg CLK_INFRA_NFI_66M>,
				 <&infracfg CLK_INFRA_ONFI>;
			clock-names = "nfi_hclk", "nfiecc_bclk", "nfi_bclk",
				      "onfi_sel", "onfi_clk26m", "onfi_mode5",
				      "onfi_mode4", "nfi_bclk_sel", "nfi_ahb_clk",
				      "nfi_1xpad_clk", "nfiecc_pclk", "nfi_pclk",
				      "onfi_pad_clk";
		};

		nfiecc: nfiecc@1100e000 {
			compatible = "mediatek,mt8163-nfiecc";
			reg = <0 0x1100e000 0 0x1000>;
			interrupts = <GIC_SPI 95 IRQ_TYPE_LEVEL_LOW>;
		};

		usb0: usb@11200000 {
			compatible = "mediatek,mt8163-usb20";
			reg = <0 0x11200000 0 0x10000>,
			      <0 0x11210000 0 0x10000>;
			interrupts = <GIC_SPI 72 IRQ_TYPE_LEVEL_LOW>;
			mode = <2>;
			multipoint = <1>;
			dyn_fifo = <1>;
			soft_con = <1>;
			dma = <1>;
			num_eps = <16>;
			dma_channels = <8>;
			clocks = <&apmixedsys CLK_APMIXED_UNIVPLL>,
				 <&infracfg CLK_INFRA_USB_MCU>,
				 <&infracfg CLK_INFRA_USB>;
			clock-names = "usbpll", "usbmcu", "usb";
		};

		audiosys: audiosys@11220000 {
			compatible = "mediatek,mt8163-audiosys", "syscon";
			reg = <0 0x11220000 0 0x1000>;
			#clock-cells = <1>;
		};

		audgpio: mt_soc_dl1_pcm@11220000 {
			compatible = "mediatek,mt8163-soc-pcm-dl1";
			reg = <0 0x11220000 0 0x1000>,
			      <0 0x11221000 0 0x9000>;
			interrupts = <GIC_SPI 142 IRQ_TYPE_LEVEL_LOW>;
			clocks = <&infracfg CLK_INFRA_AUDIO>,
				 <&topckgen CLK_TOP_AUDIO_SEL>,
				 <&topckgen CLK_TOP_AUD_INTBUS_SEL>,
				 <&topckgen CLK_TOP_AUD_1_SEL>,
				 <&topckgen CLK_TOP_AUD_2_SEL>,
				 <&topckgen CLK_TOP_APLL1>,
				 <&topckgen CLK_TOP_APLL2>,
				 <&clk26m>;
			clock-names = "aud_infra_clk",
				      "top_mux_audio",
				      "top_mux_audio_intbus",
				      "aud_mux1_clk",
				      "aud_mux2_clk",
				      "top_apll1_clk",
				      "top_apll2_clk",
				      "top_clk26m_clk";
			power-domains = <&scpsys MT8163_POWER_DOMAIN_AUDIO>;
		};

		mt_soc_dl2_pcm@11220000 {
			compatible = "mediatek,mt8163-soc-pcm-dl2";
		};

		mt_soc_ul1_pcm@11220000 {
			compatible = "mediatek,mt8163-soc-pcm-capture";
		};

		mt_soc_voice_md1@11220000 {
			compatible = "mediatek,mt8163-soc-pcm-voice-md1";
		};

		mt_soc_hdmi_pcm@11220000 {
			compatible = "mediatek,mt8163-soc-pcm-hdmi";
		};

		mt_soc_uldlloopback@11220000 {
			compatible = "mediatek,mt8163-soc-pcm-uldlloopback";
		};

		mt_soc_i2s0_pcm@11220000 {
			compatible = "mediatek,mt8163-soc-pcm-dl1-i2s0";
		};

		mt_soc_mrgrx_pcm@11220000 {
			compatible = "mediatek,mt8163-soc-pcm-mrgrx";
		};

		mt_soc_mrgrx_awb_pcm@11220000 {
			compatible = "mediatek,mt8163-soc-pcm-mrgrx-awb";
		};

		mt_soc_fm_i2s_pcm@11220000 {
			compatible = "mediatek,mt8163-soc-pcm-fm-i2s";
		};

		mt_soc_fm_i2s_awb_pcm@11220000 {
			compatible = "mediatek,mt8163-soc-pcm-fm-i2s-awb";
		};

		mt_soc_i2s0dl1_pcm@11220000 {
			compatible = "mediatek,mt8163-soc-pcm-dl1-i2s0Dl1";
		};

		mt_soc_dl1_awb_pcm@11220000 {
			compatible = "mediatek,mt8163-soc-pcm-dl1-awb";
		};

		mt_soc_voice_md1_bt@11220000 {
			compatible = "mediatek,mt8163-soc-pcm-voice-md1-bt";
		};

		mt_soc_voip_bt_out@11220000 {
			compatible = "mediatek,mt8163-soc-pcm-dl1-bt";
		};

		mt_soc_voip_bt_in@11220000 {
			compatible = "mediatek,mt8163-soc-pcm-bt-dai";
		};

		mt_soc_tdmrx_pcm@11220000 {
			compatible = "mediatek,mt8163-soc-tdm-capture";
		};

		mt_soc_fm_mrgtx_pcm@11220000 {
			compatible = "mediatek,mt8163-soc-pcm-fmtx";
		};

		mt_soc_ul2_pcm@11220000 {
			compatible = "mediatek,mt8163-soc-pcm-capture2";
		};

		mt_soc_i2s0_awb_pcm@11220000 {
			compatible = "mediatek,mt8163-soc-pcm-i2s0-awb";
		};

		mt_soc_voice_md2@11220000 {
			compatible = "mediatek,mt8163-soc-pcm-voice-md2";
		};

		mt_soc_routing_pcm@11220000 {
			compatible = "mediatek,mt8163-soc-pcm-routing";
		};

		mt_soc_voice_md2_bt@11220000 {
			compatible = "mediatek,mt8163-soc-pcm-voice-md2-bt";
		};

		mt_soc_hp_impedance@11220000 {
			compatible = "mediatek,mt8163-soc-pcm-hp-impedance";
		};

		mt_soc_codec_name@11220000 {
			compatible = "mediatek,mt8163-soc-codec-63xx";
		};

		mt_soc_dummy_pcm@11220000 {
			compatible = "mediatek,mt8163-soc-pcm-dummy";
		};

		mt_soc_codec_dummy_name@11220000 {
			compatible = "mediatek,mt8163-soc-codec-dummy";
		};

		mt_soc_routing_dai_name@11220000 {
			compatible = "mediatek,mt8163-soc-dai-routing";
		};

		mt_soc_dai_name@11220000 {
			compatible = "mediatek,mt8163-soc-dai-stub";
		};

		mfg: mfg@13000000 {
			compatible = "mediatek,mt8163-mfg", "mediatek,midgard-mfg";
			reg = <0 0x13000000 0 0x1000>;
			clocks = <&topckgen CLK_TOP_MFG_SEL>,
				 <&topckgen CLK_TOP_MMPLL>;
			clock-names = "topck", "pll";
		};

		mali: gpu@13040000 {
			compatible = "arm,malit720", "arm,mali-t72x", "arm,malit7xx", "arm,mali-midgard";
			reg = <0 0x13040000 0 0x4000>;
			interrupts = <GIC_SPI 227 IRQ_TYPE_LEVEL_LOW>,
				     <GIC_SPI 226 IRQ_TYPE_LEVEL_LOW>,
				     <GIC_SPI 225 IRQ_TYPE_LEVEL_LOW>;
			interrupt-names = "JOB", "MMU", "GPU";
			clock-frequency = <520000000>;
			power-domains = <&scpsys MT8163_POWER_DOMAIN_MFG>;
		};

		mmc0: mmc@11230000 {
			compatible = "mediatek,mt8163-mmc";
			reg = <0 0x11230000 0 0x1000>;
			interrupts = <GIC_SPI 79 IRQ_TYPE_LEVEL_LOW>;
			clocks = <&infracfg CLK_INFRA_MSDC0>,
				 <&infracfg CLK_INFRA_MSDC3>;
			clock-names = "source", "hclk";
			status = "disabled";
		};

		mmc1: mmc@11240000 {
			compatible = "mediatek,mt8163-mmc";
			reg = <0 0x11240000 0 0x1000>;
			interrupts = <GIC_SPI 80 IRQ_TYPE_LEVEL_LOW>;
			clocks = <&infracfg CLK_INFRA_MSDC1>,
				 <&clk_null>;
			clock-names = "source", "hclk";
			status = "disabled";
		};

		usb1: usb@11270000 {
			compatible = "mediatek,mt8163-usb11";
			cell-index = <1>;
			reg = <0 0x11270000 0 0x10000>,
			      <0 0x11210000 0 0x10000>;
			interrupts = <GIC_SPI 73 IRQ_TYPE_LEVEL_LOW>;
			mode = <2>;
			multipoint = <1>;
			dyn_fifo = <1>;
			soft_con = <1>;
			dma = <1>;
			num_eps = <8>;
			dma_channels = <4>;
			clocks = <&apmixedsys CLK_APMIXED_UNIVPLL>,
				 <&infracfg CLK_INFRA_USB_MCU>,
				 <&infracfg CLK_INFRA_ICUSB>;
			clock-names = "usbpll", "usbmcu", "icusb";
			status = "disabled";
		};

		mmsys: mmsys@14000000 {
			compatible = "mediatek,mt8163-mmsys", "syscon";
			reg = <0 0x14000000 0 0x1000>;
			#clock-cells = <1>;
		};

		mdp_rdma: mdp_rdma@14001000 {
			compatible = "mediatek,mt8163-mdp_rdma";
			reg = <0 0x14001000 0 0x1000>;
			interrupts = <GIC_SPI 178 IRQ_TYPE_LEVEL_LOW>;
		};

		mdp_rsz0: mdp_rsz0@14002000 {
			compatible = "mediatek,mt8163-mdp_rsz0";
			reg = <0 0x14002000 0 0x1000>;
			interrupts = <GIC_SPI 179 IRQ_TYPE_LEVEL_LOW>;
		};

		mdp_rsz1: mdp_rsz1@14003000 {
			compatible = "mediatek,mt8163-mdp_rsz1";
			reg = <0 0x14003000 0 0x1000>;
			interrupts = <GIC_SPI 180 IRQ_TYPE_LEVEL_LOW>;
		};

		mdp_wdma: mdp_wdma@14004000 {
			compatible = "mediatek,mt8163-mdp_wdma";
			reg = <0 0x14004000 0 0x1000>;
			interrupts = <GIC_SPI 182 IRQ_TYPE_LEVEL_LOW>;
		};

		mdp_wrot: mdp_wrot@14005000 {
			compatible = "mediatek,mt8163-mdp_wrot";
			reg = <0 0x14005000 0 0x1000>;
			interrupts = <GIC_SPI 183 IRQ_TYPE_LEVEL_LOW>;
		};

		mdp_tdshp: mdp_tdshp@14006000 {
			compatible = "mediatek,mt8163-mdp_tdshp0";
			reg = <0 0x14006000 0 0x1000>;
			interrupts = <GIC_SPI 181 IRQ_TYPE_LEVEL_LOW>;
		};

		dispsys: mt8163-dispsys {
			compatible = "mediatek,mt8163-dispsys";
		};

		disp_ovl0: disp_ovl0@14007000 {
			compatible = "mediatek,mt8163-disp_ovl0";
			reg = <0 0x14007000 0 0x1000>;
			interrupts = <GIC_SPI 184 IRQ_TYPE_LEVEL_LOW>;
		};

		disp_ovl1: disp_ovl1@14008000 {
			compatible = "mediatek,mt8163-disp_ovl1";
			reg = <0 0x14008000 0 0x1000>;
			interrupts = <GIC_SPI 185 IRQ_TYPE_LEVEL_LOW>;
		};

		disp_rdma0: disp_rdma0@14009000 {
			compatible = "mediatek,mt8163-disp_rdma0";
			reg = <0 0x14009000 0 0x1000>;
			interrupts = <GIC_SPI 186 IRQ_TYPE_LEVEL_LOW>;
		};

		disp_rdma1: disp_rdma1@1400a000 {
			compatible = "mediatek,mt8163-disp_rdma1";
			reg = <0 0x1400a000 0 0x1000>;
			interrupts = <GIC_SPI 187 IRQ_TYPE_LEVEL_LOW>;
		};

		disp_wdma0: disp_wdma0@1400b000 {
			compatible = "mediatek,mt8163-disp_wdma0";
			reg = <0 0x1400b000 0 0x1000>;
			interrupts = <GIC_SPI 188 IRQ_TYPE_LEVEL_LOW>;
		};

		disp_color: disp_color@1400c000 {
			compatible = "mediatek,mt8163-disp_color";
			reg = <0 0x1400c000 0 0x1000>;
			interrupts = <GIC_SPI 189 IRQ_TYPE_LEVEL_LOW>;
		};

		disp_ccorr: disp_ccorr@1400d000 {
			compatible = "mediatek,mt8163-disp_ccorr";
			reg = <0 0x1400d000 0 0x1000>;
			interrupts = <GIC_SPI 190 IRQ_TYPE_LEVEL_LOW>;
		};

		disp_aal: disp_aal@1400e000 {
			compatible = "mediatek,mt8163-disp_aal";
			reg = <0 0x1400e000 0 0x1000>;
			interrupts = <GIC_SPI 191 IRQ_TYPE_LEVEL_LOW>;
		};

		disp_gamma: disp_gamma@1400f000 {
			compatible = "mediatek,mt8163-disp_gamma";
			reg = <0 0x1400f000 0 0x1000>;
			interrupts = <GIC_SPI 192 IRQ_TYPE_LEVEL_LOW>;
		};

		disp_dither: disp_dither@14010000 {
			compatible = "mediatek,mt8163-disp_dither";
			reg = <0 0x14010000 0 0x1000>;
			interrupts = <GIC_SPI 193 IRQ_TYPE_LEVEL_LOW>;
		};

		disp_ufoe: disp_ufoe@14011000 {
			compatible = "mediatek,mt8163-disp_ufoe";
			reg = <0 0x14011000 0 0x1000>;
		};

		disp_dsi0: disp_dsi0@14012000 {
			compatible = "mediatek,mt8163-disp_dsi0";
			reg = <0 0x14012000 0 0x1000>;
			interrupts = <GIC_SPI 195 IRQ_TYPE_LEVEL_LOW>;
		};

		disp_dpi0: disp_dpi0@14013000 {
			compatible = "mediatek,mt8163-disp_dpi0";
			reg = <0 0x14013000 0 0x1000>;
			interrupts = <GIC_SPI 196 IRQ_TYPE_LEVEL_LOW>;
		};

		disp_dpi1: disp_dpi1@1401c000 {
			compatible = "mediatek,mt8163-disp_dpi1";
			reg = <0 0x1401c000 0 0x1000>;
			interrupts = <GIC_SPI 201 IRQ_TYPE_LEVEL_LOW>;
		};

		hdmi0: hdmi@1401d000 {
			compatible = "mediatek,mt8163-hdmitx";
			power-domains = <&scpsys MT8163_POWER_DOMAIN_DISP>;
			reg  =	<0 0x1401d000 0 0x1000>, /* HDMI Shell */
				<0 0x1100f000 0 0x10>, /* HDMI DDC  */
				<0 0x10013000 0 0xbc>; /* HDMI CEC  */
			interrupts = <GIC_SPI 202 IRQ_TYPE_LEVEL_LOW>;

			clocks = <&infracfg CLK_INFRA_CEC>,
				 <&infracfg CLK_INFRA_CEC_26M>,
				 <&mmsys CLK_MM_HDMI_PIXEL>,
				 <&mmsys CLK_MM_HDMI_PLLCK>,
				 <&mmsys CLK_MM_HDMI_ADSP>,
				 <&mmsys CLK_MM_HDMI_SPDIF>;

			clock-names = "cec_pdn",
				      "clk_cec_26m",
				      "mmsys_hdmi_pll",
				      "mmsys_hdmi_pixel",
				      "mmsys_hdmi_audio",
				      "mmsys_hdmi_spidif";
		};

		disp_pwm0: disp_pwm0@14014000 {
			compatible = "mediatek,mt8163-disp_pwm";
			reg = <0 0x14014000 0 0x1000>;
		};

		mm_mutex: mm_mutex@14015000 {
			compatible = "mediatek,mt8163-disp_mutex";
			reg = <0 0x14015000 0 0x1000>;
			interrupts = <GIC_SPI 177 IRQ_TYPE_LEVEL_LOW>;
		};

		disp_wdma1: disp_wdma1@14018000 {
			compatible = "mediatek,mt8163-disp_wdma1";
			reg = <0 0x14018000 0 0x1000>;
			interrupts = <GIC_SPI 198 IRQ_TYPE_LEVEL_LOW>;
		};

		disp_config2: disp_config2@10206000 {
			compatible = "mediatek,mt8163-disp_config2";
			reg = <0 0x10206000 0 0x1000>;
		};

		disp_config3: disp_config3@10000000 {
			compatible = "mediatek,mt8163-disp_config3";
			reg = <0 0x10000000 0 0x1000>;
		};

		disp_mipi: disp_mipi@10215000 {
			compatible = "mediatek,mt8163-disp_mipi";
			reg = <0 0x10215000 0 0x1000>;
		};

		disp_io_driving: disp_io_driving@10005000 {
			compatible = "mediatek,mt8163-disp_io_driving";
			reg = <0 0x10005000 0 0x1000>;
		};

		disp_tvdpll_cfg6: disp_tvdpll_cfg6@100000a0 {
			compatible = "mediatek,mt8163-disp_tvdpll_cfg6";
			reg = <0 0x100000a0 0 0x1000>;
		};

		disp_tvdpll_con0: disp_tvdpll_con0@1000c270 {
			compatible = "mediatek,mt8163-disp_tvdpll_con0";
			reg = <0 0x1000c270 0 0x1000>;
		};

		disp_tvdpll_con1: disp_tvdpll_con1@1000c274 {
			compatible = "mediatek,mt8163-disp_tvdpll_con1";
			reg = <0 0x1000c274 0 0x1000>;
		};

		disp_lvds_ana: disp_lvds_ana@10215800 {
			compatible = "mediatek,mt8163-disp_lvds_ana";
			reg = <0 0x10215800 0 0x1000>;
		};

		g3d_iommu@13005000 {
			cell-index = <2>;
			compatible = "mediatek,mt8163-g3d_iommu";
			reg = <0 0x13005000 0 0x1000>;
			interrupts = <GIC_SPI 226 IRQ_TYPE_LEVEL_LOW>;
		};

		larb0: larb@14016000 {
			compatible = "mediatek,mt8163-smi-larb";
			reg = <0 0x14016000 0 0x1000>;
			interrupts = <GIC_SPI 205 IRQ_TYPE_LEVEL_LOW>;
			mediatek,smi = <&smi_common>;
			mediatek,larbid = <0>;
			clocks = <&mmsys CLK_MM_SMI_LARB0>,
				 <&mmsys CLK_MM_SMI_LARB0>;
			clock-names = "apb", "smi";
			power-domains = <&scpsys MT8163_POWER_DOMAIN_DISP>;
		};

		smi_common: smi@14017000 {
			compatible = "mediatek,mt8163-smi";
			reg = <0 0x14017000 0 0x1000>;
			clocks = <&mmsys CLK_MM_SMI_COMMON>,
				 <&mmsys CLK_MM_SMI_COMMON>;
			clock-names = "apb", "smi";
			power-domains = <&scpsys MT8163_POWER_DOMAIN_DISP>;
		};

		met_smi: met_smi@14017000 {
			compatible = "mediatek,met_smi";
			reg = <0 0x14017000 0 0x1000>,  /* SMI_COMMON_EXT */
			      <0 0x14016000 0 0x1000>,  /* LARB 0 */
			      <0 0x16010000 0 0x1000>,  /* LARB 1 */
			      <0 0x15001000 0 0x1000>,  /* LARB 2 */
			      <0 0x17001000 0 0x1000>;  /* LARB 3 */

			clocks = <&mmsys CLK_MM_SMI_COMMON>,
				 <&mmsys CLK_MM_SMI_LARB0>,
				 <&vdecsys CLK_VDEC_CKEN>,
				 <&imgsys CLK_IMG_LARB2_SMI>,
				 <&vencsys CLK_VENC_CKE1>;

			clock-names = "smi-common",
				      "smi-larb0",
				      "vdec-larb1",
				      "img-larb2",
				      "venc-larb3";
		};

		disp_lvds_tx: disp_lvds_tx@1401b200 {
			compatible = "mediatek,mt8163-disp_lvds_tx";
			reg = <0 0x1401b200 0 0x1000>;
		};

		imgsys: imgsys@15000000 {
			compatible = "mediatek,mt8163-imgsys", "syscon";
			reg = <0 0x15000000 0 0x1000>;
			#clock-cells = <1>;
		};

		/* We need add another node to contrl DISP power in ISP driver */
		isp_display: isp_display {
			compatible = "mediatek,mt8163-isp_display";
			/*power-domains = <&scpsys MT8163_POWER_DOMAIN_DISP>;*/
		};

		ispsys: ispsys@15000000 {
			compatible = "mediatek,mt8163-ispsys";
			reg = <0 0x15004000 0 0x9000>,	/* ISP_ADDR */
			      <0 0x15000000 0 0x10000>,	/* IMGSYS_CONFIG_ADDR */
			      <0 0x10217000 0 0x3000>;	/* MIPI_ANA_ADDR */

			interrupts = <GIC_SPI 218 IRQ_TYPE_LEVEL_LOW>, /* SENINF */
				     <GIC_SPI 219 IRQ_TYPE_LEVEL_LOW>; /* CAM0 */

			clocks = <&imgsys CLK_IMG_LARB2_SMI>,
				 <&imgsys CLK_IMG_CAM_SMI>,
				 <&imgsys CLK_IMG_CAM_CAM>,
				 <&imgsys CLK_IMG_SEN_TG>,
				 <&imgsys CLK_IMG_SEN_CAM>,
				 <&imgsys CLK_IMG_CAM_SV>,
				 <&mmsys CLK_MM_SMI_COMMON>;

			clock-names = "IMG_LARB2_SMI",
				      "IMG_CAM_SMI",
				      "IMG_CAM_CAM",
				      "IMG_SEN_TG",
				      "IMG_SEN_CAM",
				      "IMG_CAM_SV",
				      "MM_SMI_COMMON";

			/* Power domains */
			/*power-domains = <&scpsys MT8163_POWER_DOMAIN_ISP>;*/
		};

		larb2: larb@15001000 {
			compatible = "mediatek,mt8163-smi-larb";
			reg = <0 0x15001000 0 0x1000>;
			interrupts = <GIC_SPI 217 IRQ_TYPE_LEVEL_LOW>;
			mediatek,smi = <&smi_common>;
			mediatek,larbid = <2>;
			clocks = <&imgsys CLK_IMG_LARB2_SMI>,
				 <&imgsys CLK_IMG_LARB2_SMI>;
			clock-names = "apb", "smi";
			power-domains = <&scpsys MT8163_POWER_DOMAIN_ISP>;
		};

		/* Main Cam */
		kd_camera_hw1: camera1@15008000 {
			compatible = "mediatek,mt8163-camera_hw";
			reg = <0 0x15008000 0 0x1000>;  /* SENINF_ADDR */

			/* Camera Common Clock Framework (CCF) */
			clocks = <&topckgen CLK_TOP_CAMTG_SEL>,
				 <&topckgen CLK_TOP_UNIVPLL_D26>,
				 <&topckgen CLK_TOP_UNIVPLL2_D2>;

			clock-names = "TOP_CAMTG_SEL",
				      "TOP_UNIVPLL_D26",
				      "TOP_UNIVPLL2_D2";
		};

		/* Sub Cam */
		kd_camera_hw2: camera2@15008000 {
			compatible = "mediatek,mt8163-camera_hw2";
			reg = <0 0x15008000 0 0x1000>;  /* SENINF_ADDR */
		};

		vdecsys: vdecsys@16000000 {
			compatible = "mediatek,mt8163-vdecsys", "syscon";
			reg = <0 0x16000000 0 0x1000>;
			#clock-cells = <1>;
		};

		vdec_gcon@16000000 {
			compatible = "mediatek,mt8163-vdec_gcon";
			reg = <0 0x16000000 0 0x10000>;
		};

		larb1: larb@16010000 {
			compatible = "mediatek,mt8163-smi-larb";
			reg = <0 0x16010000 0 0x10000>;
			interrupts = <GIC_SPI 213 IRQ_TYPE_LEVEL_LOW>;
			mediatek,smi = <&smi_common>;
			mediatek,larbid = <1>;
			clocks = <&vdecsys CLK_VDEC_CKEN>,
				 <&vdecsys CLK_VDEC_LARB_CKEN>;
			clock-names = "apb", "smi";
			power-domains = <&scpsys MT8163_POWER_DOMAIN_VDEC>;
		};

		vdec@16020000 {
			compatible = "mediatek,mt8163-vdec";
			reg = <0 0x16020000 0 0x10000>;
			interrupts = <GIC_SPI 212 IRQ_TYPE_LEVEL_LOW>;
		};

		vencsys: vencsys@17000000 {
			compatible = "mediatek,mt8163-vencsys", "syscon";
			reg = <0 0x17000000 0 0x1000>;
			#clock-cells = <1>;
		};

		larb3: larb@17001000 {
			compatible = "mediatek,mt8163-smi-larb";
			reg = <0 0x17001000 0 0x1000>;
			interrupts = <GIC_SPI 207 IRQ_TYPE_LEVEL_LOW>;
			mediatek,smi = <&smi_common>;
			mediatek,larbid = <3>;
			clocks = <&vencsys CLK_VENC_CKE1>,
				 <&vencsys CLK_VENC_CKE0>;
			clock-names = "apb", "smi";
			power-domains = <&scpsys MT8163_POWER_DOMAIN_VENC>;
		};

		venc@17002000 {
			compatible = "mediatek,mt8163-venc";
			reg = <0 0x17002000 0 0x1000>;
			interrupts = <GIC_SPI 206 IRQ_TYPE_LEVEL_LOW>;
		};

		jpgenc@17003000 {
			compatible = "mediatek,mt8163-jpgenc","mediatek,jpgenc";
			reg = <0 0x17003000 0 0x1000>;
			interrupts = <GIC_SPI 208 IRQ_TYPE_LEVEL_LOW>;
			clocks = <&vencsys CLK_VENC_CKE2>; /* jpeg enc */
			clock-names = "venc-jpgenc";
		};

		btcvsd@18000000 {
			compatible = "mediatek,mt8163-audio_bt_cvsd",
				     "mediatek,audio_bt_cvsd";
			offset = <0xf00 0x800 0xfd0 0xfd4 0xfd8>;
			/*INFRA MISC, conn_bt_cvsd_mask, cvsd_mcu_read, write, packet_indicator*/
			reg = <0 0x10001000 0 0x1000>, /*AUDIO_INFRA_BASE_PHYSICAL*/
			      <0 0x18000000 0 0x10000>, /*PKV_PHYSICAL_BASE*/
			      <0 0x18080000 0 0x8000>; /*SRAM_BANK2*/
			interrupts = <GIC_SPI 236 IRQ_TYPE_LEVEL_LOW>;
		};

		consys: consys@18070000 {
			compatible = "mediatek,mt8163-consys";
			reg = <0 0x18070000 0 0x0200>,  /*CONN_MCU_CONFIG_BASE      */
			      <0 0x10001000 0 0x1000>;  /*TOPCKGEN_BASE             */
			power-domains = <&scpsys MT8163_POWER_DOMAIN_CONN>;
			interrupts = <GIC_SPI 237 IRQ_TYPE_LEVEL_LOW>,  /* BGF_EINT */
				     <GIC_SPI 236 IRQ_TYPE_LEVEL_LOW>;  /* WDT_EINT */
			resets = <&toprgu MT8163_TOPRGU_CONN_MCU_RST>;
			reset-names = "connsys";
			status = "disabled";
		};

		wifi@180f0000 {
			compatible = "mediatek,wifi";
			reg = <0 0x180f0000 0 0x005c>;
			interrupts = <GIC_SPI 238 IRQ_TYPE_LEVEL_LOW>;
			clocks = <&infracfg CLK_INFRA_AP_DMA>;
			clock-names = "wifi-dma";
		};

		accdet: accdet@ {
			compatible = "mediatek,mt8163-accdet";
			status = "disabled";
		};

		touch: touch@ {
			compatible = "mediatek,mt8163-touch";
		};

		gps {
			compatible = "mediatek,gps";
		};

/* sensor part */
		hwmsensor@0 {
			compatible = "mediatek,hwmsensor";
		};
		gsensor@0 {
			compatible = "mediatek,gsensor";
		};
		alsps:als_ps@0 {
			compatible = "mediatek,als_ps";
		};
		batchsensor@0 {
			compatible = "mediatek,batchsensor";
		};
		gyro:gyroscope@0 {
			compatible = "mediatek,gyroscope";
		};
		barometer@0 {
			compatible = "mediatek,barometer";
		};
		msensor@0 {
			compatible = "mediatek,msensor";
		};
		orientation@0 {
			compatible = "mediatek,orientation";
		};
/* sensor end */

/*sensorhub part*/
		shf{
			compatible = "mediatek,shf";
		};
/*sensorhub end*/
		step_counter@0 {
			compatible = "mediatek,step_counter";
		};
		shake@0 {
			compatible = "mediatek,shake";
		};
		m_shk_pl@0 {
			compatible = "mediatek,m_shk_pl";
		};
		face_down@0 {
			compatible = "mediatek,face_down";
		};
		m_fdn_pl@0 {
			compatible = "mediatek,m_fdn_pl";
		};
		/* led part */
		led0:led@0 {
			compatible = "mediatek,red";
			led_mode = <3>;
			data = <6>;
			pwm_config = <0 0 0 0 0>;
		};

		led1:led@1 {
			compatible = "mediatek,green";
			led_mode = <3>;
			data = <7>;
			pwm_config = <0 0 0 0 0>;
		};

		led2:led@2 {
			compatible = "mediatek,blue";
			led_mode = <0>;
			data = < >;
			pwm_config = <0 0 0 0 0>;
		};

		led3:led@3 {
			compatible = "mediatek,jogball-backlight";
			led_mode = <0>;
			data = < >;
			pwm_config = <0 0 0 0 0>;
		};

		led4:led@4 {
			compatible = "mediatek,keyboard-backlight";
			led_mode = <0>;
			data = < >;
			pwm_config = <0 0 0 0 0>;
		};

		led5:led@5 {
			compatible = "mediatek,button-backlight";
			led_mode = <0>;
			data = < >;
			pwm_config = <0 0 0 0 0>;
		};

		led6:led@6 {
			compatible = "mediatek,lcd-backlight";
			led_mode = <5>;
			data = < >;
			pwm_config = <0 0 0 0 0>;
			gpios = <&pio 43 0>;
		};
/* led end*/

		mtkfb: mtkfb@0 {
			compatible = "mediatek,MTKFB";
			clocks =
				<&mmsys CLK_MM_FAKE_ENG>,
				<&mmsys CLK_MM_DISP_OVL0>,
				<&mmsys CLK_MM_DISP_OVL1>,
				<&mmsys CLK_MM_DISP_RDMA0>,
				<&mmsys CLK_MM_DISP_RDMA1>,
				<&mmsys CLK_MM_DISP_WDMA0>,
				<&mmsys CLK_MM_DISP_WDMA1>,
				<&mmsys CLK_MM_DISP_COLOR>,
				<&mmsys CLK_MM_DISP_CCORR>,
				<&mmsys CLK_MM_DISP_AAL>,
				<&mmsys CLK_MM_DISP_GAMMA>,
				<&mmsys CLK_MM_DISP_DITHER>,
				<&mmsys CLK_MM_DISP_UFOE>,
				<&mmsys CLK_MM_DISP_PWM_MM>,
				<&mmsys CLK_MM_DISP_PWM_26M>,
				<&mmsys CLK_MM_DSI_ENGINE>,
				<&mmsys CLK_MM_DSI_DIGITAL>,
				<&mmsys CLK_MM_DPI0_PIXEL>,
				<&mmsys CLK_MM_DPI0_ENGINE>,
				<&mmsys CLK_MM_LVDS_PIXEL>,
				<&mmsys CLK_MM_LVDS_CTS>,
				<&mmsys CLK_MM_DPI1_PIXEL>,
				<&mmsys CLK_MM_DPI1_ENGINE>,
				<&mmsys CLK_MM_DISP_DSC_ENGINE>,
				<&mmsys CLK_MM_DISP_DSC_MEM>,
				<&topckgen CLK_TOP_DPI0_SEL>,
				<&apmixedsys CLK_APMIXED_LVDSPLL>,
				<&topckgen CLK_TOP_LVDSPLL_D2>,
				<&topckgen CLK_TOP_LVDSPLL_D4>,
				<&topckgen CLK_TOP_LVDSPLL_D8>,
				<&topckgen CLK_TOP_DPI1_SEL>,
				<&apmixedsys CLK_APMIXED_TVDPLL>,
				<&topckgen CLK_TOP_TVDPLL_D2>,
				<&topckgen CLK_TOP_TVDPLL_D4>,
				<&topckgen CLK_TOP_TVDPLL_D8>,
				<&topckgen CLK_TOP_TVDPLL_D16>,
				<&topckgen CLK_TOP_PWM_SEL>;

			clock-names =
				"MMSYS_CLK_FAKE_ENG",
				"MMSYS_CLK_DISP_OVL0",
				"MMSYS_CLK_DISP_OVL1",
				"MMSYS_CLK_DISP_RDMA0",
				"MMSYS_CLK_DISP_RDMA1",
				"MMSYS_CLK_DISP_WDMA0",
				"MMSYS_CLK_DISP_WDMA1",
				"MMSYS_CLK_DISP_COLOR",
				"MMSYS_CLK_DISP_CCORR",
				"MMSYS_CLK_DISP_AAL",
				"MMSYS_CLK_DISP_GAMMA",
				"MMSYS_CLK_DISP_DITHER",
				"MMSYS_CLK_DISP_UFOE",
				"MMSYS_CLK_DISP_PWM",
				"MMSYS_CLK_DISP_PWM26M",
				"MMSYS_CLK_DSI_ENGINE",
				"MMSYS_CLK_DSI_DIGITAL",
				"MMSYS_CLK_DPI0_PIXEL",
				"MMSYS_CLK_DPI0_ENGINE",
				"MMSYS_CLK_LVDS_PIXEL",
				"MMSYS_CLK_LVDS_CTS",
				"MMSYS_CLK_DPI1_PIXEL",
				"MMSYS_CLK_DPI1_ENGINE",
				"MMSYS_CLK_DISP_DSC_ENGINE",
				"MMSYS_CLK_DISP_DSC_MEM",
				"MMSYS_CLK_MUX_DPI0_SEL",
				"MMSYS_APMIXED_LVDSPLL",
				"MMSYS_CLK_MUX_LVDSPLL_D2",
				"MMSYS_CLK_MUX_LVDSPLL_D4",
				"MMSYS_CLK_MUX_LVDSPLL_D8",
				"MMSYS_CLK_MUX_DPI1_SEL",
				"MMSYS_APMIXED_TVDPLL",
				"MMSYS_CLK_MUX_TVDPLL_D2",
				"MMSYS_CLK_MUX_TVDPLL_D4",
				"MMSYS_CLK_MUX_TVDPLL_D8",
				"MMSYS_CLK_MUX_TVDPLL_D16",
				"MMSYS_CLK_PWM_SEL";
		};

		bat_meter {
			compatible = "mediatek,bat_meter";
				/* cust_battery_meter.h */
				/* ADC resistor  */
				r_bat_sense = <4>;
				r_i_sense = <4>;
				r_charger_1 = <330>;
				r_charger_2 = <39>;
				temperature_t0 = <110>;
				temperature_t1 = <0>;
				temperature_t2 = <25>;
				temperature_t3 = <50>;
				temperature_t = <255>;	/* this should be fixed, never change the value */
				fg_meter_resistance = <0>;

			/* Qmax for 0mA */
			q_max_pos_50 = <4849>;
			q_max_pos_25 = <4904>;
			q_max_pos_0 = <4952>;
			q_max_neg_10 = <4955>;
			/* Qmax for 600mA, said high current */
			q_max_pos_50_h_current = <4815>;
			q_max_pos_25_h_current = <4867>;
			q_max_pos_0_h_current = <4396>;
			q_max_neg_10_h_current = <3124>;
			/* Discharge percentage, 1: D5, 0: D2 */
			oam_d5 = <0>;

			change_tracking_point = <1>;
			/* SW OCV tracking setting */
			cust_tracking_point = <14>;
			cust_r_sense = <200>;
			cust_hw_cc = <0>;
			aging_tuning_value = <100>;
			cust_r_fg_offset = <0>;
			ocv_board_compesate = <0>;
			r_fg_board_base = <1000>;
			r_fg_board_slope = <1000>;
			car_tune_value = <89>;

			/* HW Fuel gague  */
			current_detect_r_fg = <10>;	/* Unit: mA */
			minerroroffset = <1000>;
			fg_vbat_average_size = <18>;
			r_fg_value = <10>;	/* Unit: mOhm */

			cust_poweron_delta_capacity_tolrance = <80>;
			cust_poweron_low_capacity_tolrance = <2>;
			cust_poweron_max_vbat_tolrance = <70>;
			cust_poweron_delta_vbat_tolrance = <60>;
			cust_poweron_delta_hw_sw_ocv_capacity_tolrance = <10>;

			/* Fixed battery temperature */
			fixed_tbat_25 = <0>;
			/* Dynamic change wake up period of battery thread when suspend */
			vbat_normal_wakeup = <3600>;	/* Unit: mV */
			vbat_low_power_wakeup = <3500>;	/* Unit: mV */
			normal_wakeup_period = <5400>;	/* Unit: second */
			low_power_wakeup_period = <300>;	/* Unit: second */
			close_poweroff_wakeup_period = <30>;	/* Unit: second */

			rbat_pull_up_r = <16900>;
			rbat_pull_up_volt = <1800>;

			batt_temperature_table_num = <17>;
			batt_temperature_table = <
						(-20) 75022
						(-15) 57926
						(-10) 45168
						(-5) 35548
						0 28224
						5 22595
						10 18231
						15 14820
						20 12133
						25 10000 30 8295 35 6922 40 5810 45 4903 50 4160 55 3547 60 3039>;

			battery_profile_t0_num = <95>;
			battery_profile_t0 = <
						0  4392
						1  4368
						2  4349
						3  4332
						4  4317
						5  4302
						7  4288
						8  4273
						9  4261
						10 4247
						11 4234
						12 4221
						13 4208
						14 4196
						15 4183
						16 4171
						17 4159
						19 4147
						20 4134
						21 4122
						22 4110
						23 4099
						24 4089
						25 4079
						26 4067
						27 4054
						28 4036
						29 4018
						31 4000
						32 3984
						33 3970
						34 3960
						35 3950
						36 3942
						37 3934
						38 3925
						39 3919
						40 3911
						41 3903
						43 3895
						44 3886
						45 3879
						46 3872
						47 3865
						48 3858
						49 3852
						50 3845
						51 3839
						52 3833
						53 3828
						54 3823
						56 3818
						57 3814
						58 3810
						59 3805
						60 3800
						61 3797
						62 3794
						63 3792
						64 3789
						65 3787
						66 3785
						68 3783
						69 3782
						70 3780
						71 3778
						72 3775
						73 3773
						74 3770
						75 3767
						76 3764
						77 3761
						78 3757
						80 3753
						81 3749
						82 3744
						83 3739
						84 3733
						85 3727
						86 3720
						87 3714
						88 3708
						89 3703
						90 3700
						92 3695
						93 3691
						94 3684
						95 3671
						96 3648
						97 3608
						98 3555
						99 3497
						100 3434
						100 3368
						100 3297
						>;

			battery_profile_t1_num = <95>;
			battery_profile_t1 = <
						0  4394
						1  4372
						2  4356
						3  4341
						4  4327
						5  4314
						7  4299
						8  4286
						9  4273
						10  4260
						11  4248
						12  4234
						13  4222
						14  4209
						15  4197
						16  4184
						17  4172
						19  4160
						20  4148
						21  4136
						22  4125
						23  4112
						24  4101
						25  4090
						26  4081
						27  4071
						28  4061
						29  4047
						31  4029
						32  4012
						33  3996
						34  3984
						35  3974
						36  3965
						37  3956
						38  3947
						39  3937
						40  3928
						41  3919
						43  3909
						44  3899
						45  3890
						46  3881
						47  3873
						48  3866
						49  3859
						50  3852
						51  3846
						52  3841
						53  3835
						55  3829
						56  3825
						57  3820
						58  3816
						59  3811
						60  3807
						61  3803
						62  3800
						63  3797
						64  3793
						65  3790
						67  3787
						68  3785
						69  3783
						70  3782
						71  3780
						72  3779
						73  3777
						74  3775
						75  3772
						76  3769
						77  3766
						79  3763
						80  3760
						81  3756
						82  3751
						83  3746
						84  3740
						85  3733
						86  3726
						87  3718
						88  3710
						89  3703
						91  3699
						92  3695
						93  3691
						94  3687
						95  3680
						96  3664
						97  3626
						98  3566
						99  3479
						100  3370
						100  3241
						100  3096
						>;

			battery_profile_t2_num = <95>;
			battery_profile_t2 = <
						0  4393
						1  4374
						2  4358
						3  4343
						4  4330
						6  4263
						7  4240
						8  4228
						9  4222
						10  4200
						11  4192
						12  4182
						13  4173
						14  4160
						15  4147
						17  4125
						18  4112
						19  4102
						20  4090
						21  4080
						22  4070
						23  4060
						24  4050
						25  4040
						26  4030
						28  4008
						29  3998
						30  3985
						31  3976
						32  3966
						33  3957
						34  3948
						35  3940
						36  3932
						37  3923
						39  3903
						40  3895
						41  3884
						42  3875
						43  3868
						44  3859
						45  3852
						46  3845
						47  3840
						48  3834
						50  3823
						51  3818
						52  3813
						53  3808
						54  3804
						55  3800
						56  3795
						57  3788
						58  3787
						59  3781
						61  3775
						62  3772
						63  3769
						64  3766
						65  3762
						66  3758
						67  3756
						68  3754
						69  3750
						70  3746
						72  3740
						73  3738
						74  3725
						75  3722
						76  3719
						77  3717
						78  3716
						79  3714
						80  3712
						81  3710
						83  3708
						84  3703
						85  3697
						86  3692
						87  3685
						88  3680
						89  3671
						90  3668
						91  3665
						92  3663
						94  3657
						95  3655
						96  3650
						97  3642
						98  3638
						99  3600
						100  3379
						100  3111
						100  3065
						100  3028
						>;

			battery_profile_t3_num = <95>;
			battery_profile_t3 = <
						0  4386
						1  4355
						2  4340
						3  4326
						4  4313
						6  4299
						7  4286
						8  4273
						9  4260
						10  4247
						11  4234
						12  4221
						13  4208
						14  4195
						16  4183
						17  4170
						18  4157
						19  4145
						20  4133
						21  4120
						22  4108
						23  4097
						24  4085
						26  4074
						27  4063
						28  4051
						29  4041
						30  4030
						31  4020
						32  4009
						33  4000
						35  3990
						36  3981
						37  3972
						38  3963
						39  3955
						40  3946
						41  3937
						42  3928
						43  3917
						45  3900
						46  3885
						47  3876
						48  3868
						49  3860
						50  3854
						51  3847
						52  3841
						53  3836
						55  3831
						56  3826
						57  3821
						58  3816
						59  3812
						60  3808
						61  3803
						62  3800
						63  3797
						65  3793
						66  3790
						67  3787
						68  3783
						69  3780
						70  3777
						71  3774
						72  3766
						73  3757
						75  3751
						76  3746
						77  3742
						78  3736
						79  3732
						80  3728
						81  3725
						82  3720
						84  3715
						85  3708
						86  3702
						87  3696
						88  3688
						89  3679
						90  3676
						91  3676
						92  3674
						94  3673
						95  3670
						96  3659
						97  3620
						98  3565
						99  3490
						100  3377
						100  3136
						100  3026
						100  3026
						100  3026
						>;

			r_profile_t0_num = <95>;
			r_profile_t0 = <
						743  4392
						743  4368
						742  4349
						737  4332
						733  4317
						729  4302
						719  4288
						713  4273
						710  4261
						703  4247
						696  4234
						692  4221
						685  4208
						681  4196
						676  4183
						672  4171
						669  4159
						665  4147
						659  4134
						654  4122
						652  4110
						649  4099
						648  4089
						647  4079
						648  4067
						645  4054
						633  4036
						625  4018
						615  4000
						609  3984
						603  3970
						601  3960
						603  3950
						603  3942
						600  3934
						599  3925
						599  3919
						598  3911
						598  3903
						598  3895
						597  3886
						598  3879
						599  3872
						601  3865
						601  3858
						602  3852
						604  3845
						609  3839
						612  3833
						615  3828
						617  3823
						620  3818
						625  3814
						629  3810
						631  3805
						635  3800
						640  3797
						646  3794
						653  3792
						660  3789
						669  3787
						676  3785
						684  3783
						694  3782
						705  3780
						714  3778
						726  3775
						739  3773
						753  3770
						768  3767
						783  3764
						804  3761
						825  3757
						843  3753
						868  3749
						894  3744
						921  3739
						949  3733
						979  3727
						1007  3720
						1039  3714
						1069  3708
						1096  3703
						1127  3700
						1159  3695
						1194  3691
						1234  3684
						1283  3671
						1347  3648
						1360  3608
						1194  3555
						1027  3497
						922  3434
						812  3368
						694  3297
						>;

			r_profile_t1_num = <95>;
			r_profile_t1 = <
						379  4394
						379  4372
						376  4356
						373  4341
						370  4327
						366  4314
						362  4299
						359  4286
						354  4273
						351  4260
						351  4248
						347  4234
						346  4222
						345  4209
						343  4197
						340  4184
						341  4172
						341  4160
						339  4148
						339  4136
						339  4125
						337  4112
						338  4101
						337  4090
						341  4081
						345  4071
						348  4061
						348  4047
						340  4029
						334  4012
						330  3996
						328  3984
						327  3974
						327  3965
						325  3956
						319  3947
						315  3937
						313  3928
						312  3919
						309  3909
						306  3899
						304  3890
						303  3881
						303  3873
						303  3866
						303  3859
						304  3852
						304  3846
						305  3841
						308  3835
						308  3829
						311  3825
						312  3820
						313  3816
						316  3811
						316  3807
						320  3803
						322  3800
						325  3797
						327  3793
						329  3790
						331  3787
						334  3785
						337  3783
						343  3782
						345  3780
						349  3779
						355  3777
						359  3775
						364  3772
						369  3769
						374  3766
						382  3763
						391  3760
						399  3756
						408  3751
						421  3746
						433  3740
						445  3733
						461  3726
						480  3718
						501  3710
						525  3703
						558  3699
						598  3695
						648  3691
						715  3687
						803  3680
						914  3664
						1016  3626
						1102  3566
						1122  3479
						959  3370
						744  3241
						502  3096
						>;

			r_profile_t2_num = <95>;
			r_profile_t2 = <
						128  4393
						128  4374
						128  4358
						126  4343
						126  4330
						128  4317
						127  4302
						126  4289
						126  4276
						126  4263
						127  4250
						126  4236
						128  4224
						128  4211
						128  4198
						127  4185
						128  4172
						129  4160
						129  4147
						130  4136
						131  4123
						130  4111
						131  4099
						133  4088
						134  4077
						136  4068
						138  4057
						139  4045
						140  4032
						140  4020
						144  4009
						142  3999
						143  3989
						144  3980
						145  3971
						147  3965
						148  3956
						151  3947
						149  3937
						145  3925
						139  3912
						132  3899
						128  3887
						125  3877
						125  3870
						123  3862
						122  3855
						122  3849
						121  3843
						122  3838
						122  3833
						123  3828
						124  3824
						123  3819
						124  3815
						126  3811
						126  3808
						128  3805
						127  3800
						128  3797
						128  3794
						127  3791
						129  3788
						129  3786
						129  3783
						129  3780
						127  3776
						126  3772
						126  3769
						124  3764
						123  3760
						123  3756
						124  3752
						125  3748
						126  3745
						126  3741
						124  3734
						124  3728
						125  3721
						126  3715
						126  3707
						123  3697
						122  3694
						123  3693
						125  3692
						129  3690
						132  3688
						134  3676
						129  3638
						132  3581
						140  3501
						153  3379
						0    3111
						0    3065
						0    3028
						>;

			r_profile_t3_num = <95>;
			r_profile_t3 = <
						104  4386
						104  4355
						104  4340
						102  4326
						104  4313
						103  4299
						102  4286
						102  4273
						104  4260
						103  4247
						103  4234
						106  4221
						104  4208
						104  4195
						106  4183
						106  4170
						105  4157
						105  4145
						105  4133
						105  4120
						105  4108
						106  4097
						108  4085
						107  4074
						107  4063
						108  4051
						110  4041
						109  4030
						110  4020
						111  4009
						112  4000
						111  3990
						113  3981
						114  3972
						115  3963
						116  3955
						118  3946
						120  3937
						121  3928
						120  3917
						112  3900
						106  3885
						106  3876
						106  3868
						104  3860
						104  3854
						104  3847
						104  3841
						104  3836
						106  3831
						105  3826
						105  3821
						105  3816
						107  3812
						107  3808
						107  3803
						108  3800
						109  3797
						110  3793
						111  3790
						111  3787
						111  3783
						111  3780
						111  3777
						111  3774
						107  3766
						105  3757
						107  3751
						106  3746
						107  3742
						105  3736
						106  3732
						104  3728
						105  3725
						106  3720
						108  3715
						107  3708
						107  3702
						108  3696
						106  3688
						105  3679
						105  3676
						105  3676
						110  3674
						113  3673
						117  3670
						117  3659
						111  3620
						112  3565
						115  3490
						124  3377
						223  3136
						41  3026
						41  3026
						41  3026
						>;

		};
		bat_meter1 {
			compatible = "mediatek,bat_meter1";
			/* cust_battery_meter.h */
			/* ADC resistor  */
			r_bat_sense = <4>;
			r_i_sense = <4>;
			r_charger_1 = <330>;
			r_charger_2 = <39>;
			temperature_t0 = <110>;
			temperature_t1 = <0>;
			temperature_t2 = <25>;
			temperature_t3 = <50>;
			temperature_t = <255>;	/* this should be fixed, never change the value */
			fg_meter_resistance = <0>;

			/* Qmax for 0mA */
			q_max_pos_50 = <4923>;
			q_max_pos_25 = <4984>;
			q_max_pos_0 = <4923>;
			q_max_neg_10 = <4806>;
			/* Qmax for 600mA, said high current */
			q_max_pos_50_h_current = <4886>;
			q_max_pos_25_h_current = <4934>;
			q_max_pos_0_h_current = <4357>;
			q_max_neg_10_h_current = <2288>;
			/* Discharge percentage, 1: D5, 0: D2 */
			oam_d5 = <0>;

			change_tracking_point = <1>;
			/* SW OCV tracking setting */
			cust_tracking_point = <14>;
			cust_r_sense = <200>;
			cust_hw_cc = <0>;
			aging_tuning_value = <100>;
			cust_r_fg_offset = <0>;
			ocv_board_compesate = <0>;
			r_fg_board_base = <1000>;
			r_fg_board_slope = <1000>;
			car_tune_value = <89>;

			/* HW Fuel gague  */
			current_detect_r_fg = <10>;	/* Unit: mA */
			minerroroffset = <1000>;
			fg_vbat_average_size = <18>;
			r_fg_value = <10>;	/* Unit: mOhm */

			cust_poweron_delta_capacity_tolrance = <80>;
			cust_poweron_low_capacity_tolrance = <2>;
			cust_poweron_max_vbat_tolrance = <70>;
			cust_poweron_delta_vbat_tolrance = <60>;
			cust_poweron_delta_hw_sw_ocv_capacity_tolrance = <10>;

			/* Fixed battery temperature */
			fixed_tbat_25 = <0>;
			/* Dynamic change wake up period of battery thread when suspend */
			vbat_normal_wakeup = <3600>;	/* Unit: mV */
			vbat_low_power_wakeup = <3500>;	/* Unit: mV */
			normal_wakeup_period = <5400>;	/* Unit: second */
			low_power_wakeup_period = <300>;	/* Unit: second */
			close_poweroff_wakeup_period = <30>;	/* Unit: second */

			rbat_pull_up_r = <16900>;
			rbat_pull_up_volt = <1800>;

			batt_temperature_table_num = <17>;
			batt_temperature_table = <
						(-20) 75022
						(-15) 57926
						(-10) 45168
						(-5) 35548
						0 28224
						5 22595
						10 18231
						15 14820
						20 12133
						25 10000 30 8295 35 6922 40 5810 45 4903 50 4160 55 3547 60 3039>;

			battery_profile_t0_num = <95>;
			battery_profile_t0 = <
						0    4382
						1    4354
						2    4333
						3    4315
						4    4299
						6    4285
						7    4270
						8    4256
						9    4242
						10   4229
						11   4216
						12   4203
						13   4191
						15   4179
						16   4167
						17   4155
						18   4143
						19   4131
						20   4119
						21   4108
						22   4097
						24   4088
						25   4078
						26   4066
						27   4052
						28   4034
						29   4016
						30   3999
						31   3983
						33   3970
						34   3960
						35   3950
						36   3942
						37   3935
						38   3927
						39   3920
						40   3912
						42   3905
						43   3897
						44   3889
						45   3882
						46   3874
						47   3867
						48   3861
						49   3854
						51   3848
						52   3842
						53   3837
						54   3832
						55   3826
						56   3822
						57   3817
						58   3813
						60   3808
						61   3805
						62   3801
						63   3798
						64   3795
						65   3792
						66   3790
						67   3788
						69   3785
						70   3783
						71   3781
						72   3779
						73   3777
						74   3775
						75   3772
						76   3770
						78   3767
						79   3764
						80   3762
						81   3758
						82   3755
						83   3751
						84   3746
						85   3742
						87   3736
						88   3731
						89   3725
						90   3719
						91   3714
						92   3709
						93   3705
						94   3701
						96   3696
						97   3690
						98   3681
						99   3600
						100  3389
						100  3389
						100  3358
						100  3340
						100  3340
						100  3340
						>;

			battery_profile_t1_num = <95>;
			battery_profile_t1 = <
						0   4381
						1   4357
						2   4338
						3   4322
						4   4307
						5   4293
						7   4279
						8   4266
						9   4253
						10  4240
						11  4227
						12  4215
						13  4202
						14  4191
						15  4179
						16  4167
						18  4155
						19  4143
						20  4131
						21  4120
						22  4108
						23  4097
						24  4088
						25  4080
						26  4072
						27  4060
						29  4043
						30  4023
						31  4006
						32  3992
						33  3981
						34  3972
						35  3964
						36  3957
						37  3950
						38  3942
						40  3933
						41  3923
						42  3913
						43  3903
						44  3894
						45  3884
						46  3876
						47  3868
						48  3861
						49  3854
						51  3848
						52  3842
						53  3837
						54  3831
						55  3826
						56  3822
						57  3817
						58  3813
						59  3810
						60  3806
						62  3802
						63  3799
						64  3796
						65  3793
						66  3790
						67  3788
						68  3786
						69  3785
						70  3783
						71  3781
						73  3780
						74  3778
						75  3776
						76  3774
						77  3771
						78  3769
						79  3766
						80  3762
						81  3759
						82  3754
						84  3749
						85  3744
						86  3738
						87  3732
						88  3725
						89  3717
						90  3709
						91  3704
						92  3699
						93  3696
						95  3693
						96  3688
						97  3678
						98  3653
						99  3608
						100  3389
						100  3389
						100  3389
						100  3389
						>;

			battery_profile_t2_num = <95>;
			battery_profile_t2 = <
						0  4379
						1  4356
						2  4338
						3  4322
						4  4307
						5  4293
						7  4280
						8  4266
						9  4253
						10  4240
						11  4227
						12  4215
						13  4202
						14  4190
						15  4177
						16  4165
						18  4153
						19  4141
						20  4129
						21  4116
						22  4105
						23  4094
						24  4082
						25  4072
						26  4065
						27  4056
						29  4041
						30  4023
						31  4009
						32  3997
						33  3988
						34  3982
						35  3976
						36  3969
						37  3961
						38  3952
						40  3944
						41  3935
						42  3925
						43  3914
						44  3902
						45  3890
						46  3878
						47  3868
						48  3860
						49  3853
						50  3846
						52  3841
						53  3836
						54  3830
						55  3825
						56  3821
						57  3816
						58  3812
						59  3808
						60  3805
						61  3801
						63  3797
						64  3795
						65  3792
						66  3789
						67  3787
						68  3783
						69  3780
						70  3779
						71  3775
						72  3773
						74  3769
						75  3766
						76  3763
						77  3759
						78  3755
						79  3751
						80  3747
						81  3744
						82  3739
						83  3734
						84  3728
						86  3721
						87  3715
						88  3708
						89  3699
						90  3693
						91  3691
						92  3690
						93  3689
						94  3686
						95  3679
						97  3649
						98  3596
						99  3522
						100 3379
						100 3278
                                                100 3278
                                                100 3108
						>;

			battery_profile_t3_num = <95>;
			battery_profile_t3 = <
						0  4366
						1  4343
						2  4324
						3  4307
						4  4292
						5  4278
						7  4264
						8  4250
						9  4237
						10  4225
						11  4212
						12  4200
						13  4187
						14  4174
						15  4162
						16  4150
						18  4138
						19  4126
						20  4114
						21  4102
						22  4091
						23  4080
						24  4069
						25  4058
						26  4047
						27  4036
						29  4026
						30  4017
						31  4007
						32  3997
						33  3987
						34  3978
						35  3969
						36  3961
						37  3953
						38  3945
						39  3937
						41  3929
						42  3921
						43  3912
						44  3902
						45  3887
						46  3873
						47  3862
						48  3855
						49  3848
						50  3842
						52  3836
						53  3831
						54  3826
						55  3821
						56  3816
						57  3813
						58  3808
						59  3804
						60  3800
						61  3797
						63  3793
						64  3790
						65  3787
						66  3784
						67  3782
						68  3780
						69  3777
						70  3774
						71  3771
						72  3766
						73  3757
						75  3750
						76  3746
						77  3742
						78  3738
						79  3733
						80  3729
						81  3725
						82  3722
						83  3717
						84  3712
						86  3704
						87  3699
						88  3692
						89  3683
						90  3677
						91  3676
						92  3674
						93  3673
						94  3671
						95  3665
						97  3638
						98  3589
						99  3522
						100  3389
						100  3266
						100  3266
						100  3266
						>;

			r_profile_t0_num = <95>;
			r_profile_t0 = <
						963 4382
						963 4354
						1033 4333
						962 4315
						925 4299
						1070 4285
						995 4270
						982 4256
						973 4242
						965 4229
						952 4216
						937 4203
						932 4191
						923 4179
						913 4167
						898 4155
						895 4143
						853 4131
						873 4119
						872 4108
						867 4097
						858 4088
						852 4078
						850 4066
						845 4052
						827 4034
						817 4016
						812 3999
						805 3983
						795 3970
						792 3960
						793 3950
						792 3942
						792 3935
						790 3927
						787 3920
						782 3912
						782 3905
						778 3897
						778 3889
						780 3882
						775 3874
						772 3867
						780 3861
						777 3854
						775 3848
						783 3842
						777 3837
						788 3832
						780 3826
						792 3822
						785 3817
						797 3813
						793 3808
						802 3805
						802 3801
						802 3798
						817 3795
						813 3792
						817 3790
						827 3788
						822 3785
						837 3783
						845 3781
						842 3779
						858 3777
						873 3775
						882 3772
						887 3770
						888 3767
						898 3764
						908 3762
						920 3758
						930 3755
						943 3751
						957 3746
						972 3742
						983 3736
						1008 3731
						1015 3725
						1042 3719
						1068 3714
						1087 3709
						1133 3705
						1163 3701
						1203 3696
						1260 3690
						1298 3681
						1365 3665
						1427 3639
						1427 3639
						1427 3639
						1427 3639
						1427 3639
						1427 3639
						>;

			r_profile_t1_num = <95>;
			r_profile_t1 = <
						507 4381
						507 4357
						503 4338
						500 4322
						495 4307
						492 4293
						485 4279
						478 4266
						472 4253
						465 4240
						462 4227
						458 4215
						455 4202
						452 4191
						448 4179
						443 4167
						438 4155
						435 4143
						430 4131
						432 4120
						428 4108
						425 4097
						425 4088
						425 4080
						427 4072
						423 4060
						415 4043
						407 4023
						402 4006
						402 3992
						400 3981
						402 3972
						402 3964
						402 3957
						400 3950
						395 3942
						393 3933
						388 3923
						385 3913
						383 3903
						382 3894
						377 3884
						377 3876
						375 3868
						375 3861
						377 3854
						378 3848
						378 3842
						382 3837
						383 3831
						383 3826
						387 3822
						387 3817
						392 3813
						397 3810
						398 3806
						402 3802
						405 3799
						408 3796
						410 3793
						413 3790
						417 3788
						420 3786
						425 3785
						430 3783
						432 3781
						438 3780
						438 3778
						442 3776
						445 3774
						450 3771
						458 3769
						463 3766
						468 3762
						477 3759
						480 3754
						487 3749
						495 3744
						502 3738
						515 3732
						528 3725
						540 3717
						553 3709
						573 3704
						597 3699
						625 3696
						663 3693
						715 3688
						778 3678
						852 3653
						947 3608
						1087 3540
						1087 3540
						1087 3540
						1087 3540
						>;

			r_profile_t2_num = <92>;
			r_profile_t2 = <
						165 4356
						165 4338
						165 4322
						163 4307
						162 4293
						163 4280
						162 4266
						162 4253
						162 4240
						162 4227
						165 4215
						165 4202
						167 4190
						165 4177
						165 4165
						165 4153
						165 4141
						163 4129
						163 4116
						163 4105
						165 4094
						163 4082
						163 4072
						168 4065
						170 4056
						167 4041
						160 4023
						163 4009
						167 3997
						170 3988
						170 3982
						172 3976
						173 3969
						173 3961
						172 3952
						175 3944
						177 3935
						175 3925
						172 3914
						167 3902
						162 3990
						157 3878
						152 3868
						152 3860
						152 3853
						150 3846
						152 3841
						152 3836
						152 3830
						152 3825
						153 3821
						155 3816
						155 3812
						155 3808
						157 3805
						157 3801
						153 3897
						155 3795
						158 3792
						158 3789
						160 3787
						160 3783
						160 3780
						160 3779
						157 3775
						158 3773
						158 3769
						157 3766
						157 3763
						158 3759
						160 3755
						160 3751
						160 3747
						163 3744
						162 3739
						162 3734
						165 3728
						165 3721
						167 3715
						168 3708
						170 3799
						168 3693
						172 3691
						177 3690
						183 3689
						190 3686
						193 3679
						188 3649
						197 3696
						213 3522
						238 3411
						372 3178
						>;

			r_profile_t3_num = <95>;
			r_profile_t3 = <
						112 4366
						112 4343
						110 4324
						110 4307
						110 4292
						112 4278
						110 4264
						108 4250
						110 4237
						112 4225
						110 4212
						112 4200
						112 4187
						110 4174
						112 4162
						112 4150
						112 4138
						113 4126
						112 4114
						112 4102
						113 4091
						113 4080
						115 4069
						115 4058
						115 4047
						113 4036
						115 4026
						117 4017
						117 4007
						117 3997
						117 3987
						118 3978
						117 3969
						120 3961
						122 3953
						123 3945
						125 3937
						125 3929
						128 3921
						128 3912
						127 3902
						122 3887
						115 3873
						112 3862
						112 3855
						110 3848
						112 3842
						110 3836
						110 3831
						112 3826
						112 3821
						110 3816
						113 3813
						112 3808
						112 3804
						113 3800
						113 3797
						113 3793
						115 3790
						115 3787
						115 3784
						117 3782
						118 3780
						118 3777
						118 3774
						118 3771
						117 3766
						113 3757
						112 3750
						113 3746
						113 3742
						115 3738
						113 3733
						113 3729
						113 3725
						115 3722
						115 3717
						117 3712
						113 3704
						117 3699
						115 3692
						115 3683
						112 3677
						115 3676
						113 3674
						118 3673
						123 3671
						127 3665
						120 3638
						122 3589
						123 3522
						133 3428
						160 3266
						160 3266
						160 3266
						>;

		};

		BAT_NOTIFY {
			compatible = "mediatek,bat_notify";
		};

		bat_comm: bat_comm {
			compatible = "mediatek,battery";
		};

		dumchar {
			compatible = "mediatek,mt8163-dummy_char";
		};

		/* flashlight  */
		/*flashlight: flashlight@ {
			compatible = "mediatek,camera_flashlight";
		};*/

		ice: ice_debug {
			compatible = "mediatek,mt8163-ice_debug",
				     "mediatek,mt8173-ice_debug";
			clocks = <&infracfg CLK_INFRA_DEBUGSYS>;
			clock-names = "ice_dbg";
		};

		/* for sysram dev and pipemgr dev */
		isp_pipemgr {
			compatible = "mediatek,mt8163-isp_pipemgr";
		};

		isp_sysram {
			compatible = "mediatek,mt8163-isp_sysram";
		};

		mtee {
			compatible = "mediatek,mtee";
			clocks = <&infracfg CLK_INFRA_GCPU>;
			clock-names = "GCPU";
		};
	};

	lcm: lcm {
		compatible = "mediatek,lcm";
	};
};

